VERSION ""

NS_ :

BS_:

BU_: PDCM TCU EMS GCU MCUF MCUR SWM ExternalTool

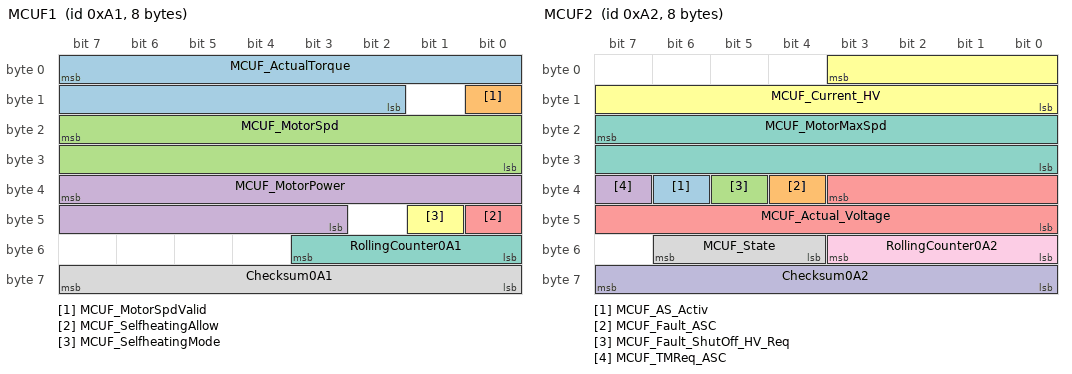
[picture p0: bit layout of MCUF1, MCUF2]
BO_ 161 MCUF1: 8 MCUF
 SG_ MCUF_ActualTorque : 7|14@0+ (0.1,-450) [-450|450] "Nm"  PDCM,TCU
 SG_ MCUF_MotorSpdValid : 8|1@0+ (1,0) [0|1] ""  PDCM,TCU
 SG_ MCUF_MotorSpd : 23|16@0+ (1,-20000) [-20000|20000] "rpm"  PDCM,TCU
 SG_ MCUF_MotorPower : 39|13@0+ (0.1,-260) [-260|260] "Kw"  PDCM,TCU
 SG_ MCUF_SelfheatingAllow : 40|1@0+ (1,0) [0|1] ""  PDCM
 SG_ MCUF_SelfheatingMode : 41|1@0+ (1,0) [0|1] ""  PDCM
 SG_ RollingCounter0A1 : 51|4@0+ (1,0) [0|15] ""  PDCM,TCU
 SG_ Checksum0A1 : 63|8@0+ (1,0) [0|255] ""  PDCM,TCU

BO_ 162 MCUF2: 8 MCUF
 SG_ MCUF_AS_Activ : 38|1@0+ (1,0) [0|1] ""  PDCM
 SG_ MCUF_Fault_ASC : 36|1@0+ (1,0) [0|1] ""  PDCM
 SG_ MCUF_Fault_ShutOff_HV_Req : 37|1@0+ (1,0) [0|1] ""  PDCM
 SG_ MCUF_TMReq_ASC : 39|1@0+ (1,0) [0|1] ""  PDCM
 SG_ MCUF_Actual_Voltage : 35|12@0+ (0.25,0) [0|1023.25] "V"  PDCM
 SG_ MCUF_Current_HV : 3|12@0+ (0.5,-1023) [-1023|1023.5] "Unit_Amper"  PDCM
 SG_ MCUF_MotorMaxSpd : 23|16@0+ (1,-20000) [-20000|20000] "rpm"  PDCM
 SG_ MCUF_State : 54|3@0+ (1,0) [0|7] ""  PDCM
 SG_ RollingCounter0A2 : 51|4@0+ (1,0) [0|15] ""  PDCM
 SG_ Checksum0A2 : 63|8@0+ (1,0) [0|255] ""  PDCM

BO_ 164 MCUF_SelfHeat2: 8 MCUF
 SG_ MCUF_BusCurrent : 18|11@0+ (0.5,0) [0|800] "Arms"  PDCM
 SG_ MCUF_BusFreq : 35|12@0+ (1,0) [0|4000] "Hz"  PDCM

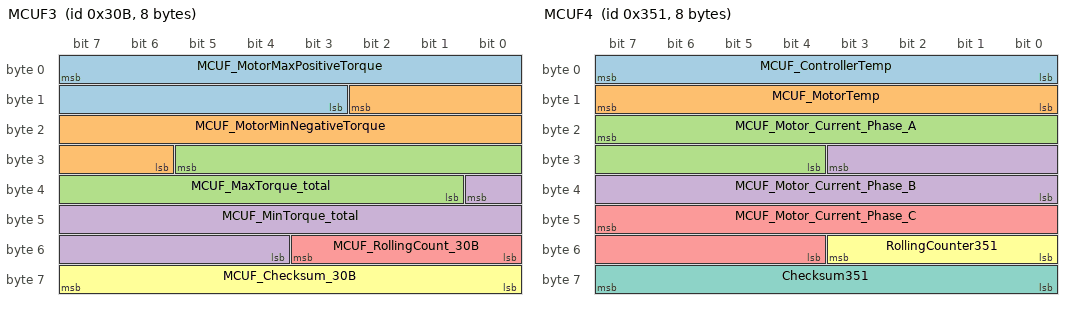
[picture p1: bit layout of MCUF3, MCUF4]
BO_ 779 MCUF3: 8 MCUF
 SG_ MCUF_MotorMaxPositiveTorque : 7|13@0+ (0.1,0) [0|450] ""  PDCM
 SG_ MCUF_MotorMinNegativeTorque : 10|13@0+ (0.1,-450) [-450|0] ""  PDCM
 SG_ MCUF_MaxTorque_total : 29|13@0+ (0.1,0) [0|450] "Unit_NewtoMeter"  PDCM
 SG_ MCUF_MinTorque_total : 32|13@0+ (0.1,-450) [-450|0] "Unit_NewtoMeter"  PDCM
 SG_ MCUF_RollingCount_30B : 51|4@0+ (1,0) [0|15] ""  PDCM
 SG_ MCUF_Checksum_30B : 63|8@0+ (1,0) [0|255] ""  PDCM

BO_ 849 MCUF4: 8 MCUF
 SG_ MCUF_ControllerTemp : 7|8@0+ (1,-40) [-40|214] "℃"  PDCM
 SG_ MCUF_MotorTemp : 15|8@0+ (1,-40) [-40|214] "℃"  PDCM,TCU
 SG_ MCUF_Motor_Current_Phase_A : 23|12@0+ (1,-1200) [-1200|1200] "Unit_Amper"  Vector__XXX
 SG_ MCUF_Motor_Current_Phase_B : 27|12@0+ (1,-1200) [-1200|1200] "Unit_Amper"  Vector__XXX
 SG_ MCUF_Motor_Current_Phase_C : 47|12@0+ (1,-1200) [-1200|1200] "Unit_Amper"  Vector__XXX
 SG_ RollingCounter351 : 51|4@0+ (1,0) [0|15] ""  PDCM,TCU
 SG_ Checksum351 : 63|8@0+ (1,0) [0|255] ""  PDCM,TCU

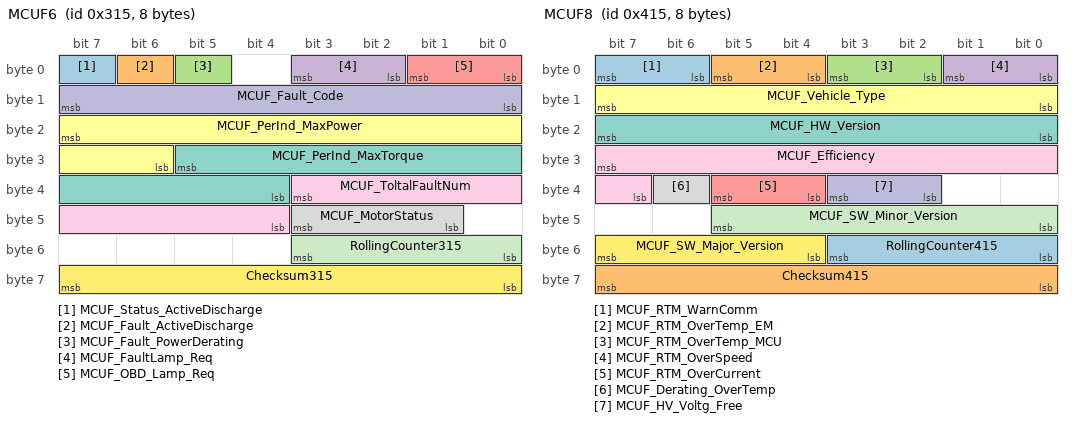
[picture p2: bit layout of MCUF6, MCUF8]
BO_ 789 MCUF6: 8 MCUF
 SG_ MCUF_Status_ActiveDischarge : 7|1@0+ (1,0) [0|1] ""  PDCM
 SG_ MCUF_Fault_ActiveDischarge : 6|1@0+ (1,0) [0|1] ""  PDCM
 SG_ MCUF_Fault_PowerDerating : 5|1@0+ (1,0) [0|1] ""  PDCM
 SG_ MCUF_FaultLamp_Req : 3|2@0+ (1,0) [0|3] ""  PDCM
 SG_ MCUF_OBD_Lamp_Req : 1|2@0+ (1,0) [0|3] ""  PDCM
 SG_ MCUF_PerInd_MaxPower : 23|10@0+ (0.2,0) [0|200] "Unit_Percent"  PDCM
 SG_ MCUF_PerInd_MaxTorque : 29|10@0+ (0.2,0) [0|200] "Unit_Percent"  PDCM
 SG_ MCUF_MotorStatus : 43|3@0+ (1,0) [0|7] ""  PDCM
 SG_ MCUF_ToltalFaultNum : 35|8@0+ (1,0) [0|252] ""  PDCM
 SG_ MCUF_Fault_Code : 15|8@0+ (1,0) [0|255] ""  PDCM
 SG_ RollingCounter315 : 51|4@0+ (1,0) [0|15] ""  PDCM
 SG_ Checksum315 : 63|8@0+ (1,0) [0|255] ""  PDCM

BO_ 787 MCUF_SelfHeat1: 8 MCUF
 SG_ MCUF_UdFreq : 2|11@0+ (1,0) [0|2000] "Hz"  PDCM
 SG_ MCUF_UdVolt : 21|14@0+ (0.1,-500) [-500|500] "V"  PDCM

BO_ 1045 MCUF8: 8 MCUF
 SG_ MCUF_RTM_WarnComm : 7|2@0+ (1,0) [0|3] ""  PDCM
 SG_ MCUF_RTM_OverTemp_EM : 5|2@0+ (1,0) [0|3] ""  PDCM
 SG_ MCUF_RTM_OverTemp_MCU : 3|2@0+ (1,0) [0|3] ""  PDCM
 SG_ MCUF_RTM_OverSpeed : 1|2@0+ (1,0) [0|3] ""  PDCM
 SG_ MCUF_RTM_OverCurrent : 37|2@0+ (1,0) [0|3] ""  PDCM
 SG_ MCUF_Vehicle_Type : 15|8@0+ (1,0) [0|255] ""  PDCM
 SG_ MCUF_HW_Version : 23|8@0+ (1,0) [0|255] ""  PDCM
 SG_ MCUF_Derating_OverTemp : 38|1@0+ (1,0) [0|1] ""  PDCM
 SG_ MCUF_Efficiency : 31|9@0+ (0.2,0) [0|101.8] "Unit_Percent"  PDCM
 SG_ MCUF_HV_Voltg_Free : 35|2@0+ (1,0) [0|3] ""  PDCM
 SG_ MCUF_SW_Minor_Version : 45|6@0+ (1,0) [0|63] ""  PDCM
 SG_ MCUF_SW_Major_Version : 55|4@0+ (1,0) [0|15] ""  PDCM
 SG_ RollingCounter415 : 51|4@0+ (1,0) [0|15] ""  PDCM
 SG_ Checksum415 : 63|8@0+ (1,0) [0|255] ""  PDCM

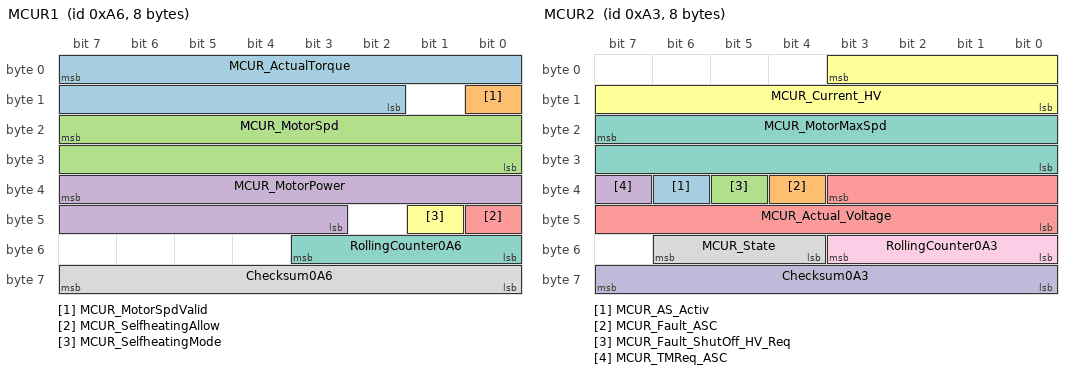
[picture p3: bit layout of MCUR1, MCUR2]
BO_ 166 MCUR1: 8 MCUR
 SG_ MCUR_ActualTorque : 7|14@0+ (0.1,-450) [-450|450] "Nm"  PDCM
 SG_ MCUR_MotorSpdValid : 8|1@0+ (1,0) [0|1] ""  PDCM
 SG_ MCUR_MotorSpd : 23|16@0+ (1,-20000) [-20000|20000] "rpm"  PDCM
 SG_ MCUR_MotorPower : 39|13@0+ (0.1,-260) [-260|260] "Kw"  PDCM
 SG_ MCUR_SelfheatingAllow : 40|1@0+ (1,0) [0|1] ""  PDCM
 SG_ MCUR_SelfheatingMode : 41|1@0+ (1,0) [0|1] ""  PDCM
 SG_ RollingCounter0A6 : 51|4@0+ (1,0) [0|15] ""  PDCM
 SG_ Checksum0A6 : 63|8@0+ (1,0) [0|255] ""  PDCM

BO_ 163 MCUR2: 8 MCUR
 SG_ MCUR_AS_Activ : 38|1@0+ (1,0) [0|1] ""  PDCM
 SG_ MCUR_Fault_ASC : 36|1@0+ (1,0) [0|1] ""  PDCM
 SG_ MCUR_Fault_ShutOff_HV_Req : 37|1@0+ (1,0) [0|1] ""  PDCM
 SG_ MCUR_TMReq_ASC : 39|1@0+ (1,0) [0|1] ""  PDCM
 SG_ MCUR_Actual_Voltage : 35|12@0+ (0.25,0) [0|1023.25] "V"  PDCM
 SG_ MCUR_Current_HV : 3|12@0+ (0.5,-1023) [-1023|1023.5] "Unit_Amper"  PDCM
 SG_ MCUR_MotorMaxSpd : 23|16@0+ (1,-20000) [-20000|20000] "rpm"  PDCM
 SG_ MCUR_State : 54|3@0+ (1,0) [0|7] ""  PDCM
 SG_ RollingCounter0A3 : 51|4@0+ (1,0) [0|15] ""  PDCM
 SG_ Checksum0A3 : 63|8@0+ (1,0) [0|255] ""  PDCM

BO_ 785 MCUR_SelfHeat2: 8 MCUR
 SG_ MCUR_BusCurrent : 18|11@0+ (0.5,0) [0|800] "Arms"  PDCM
 SG_ MCUR_BusFreq : 35|12@0+ (1,0) [0|4000] "Hz"  PDCM

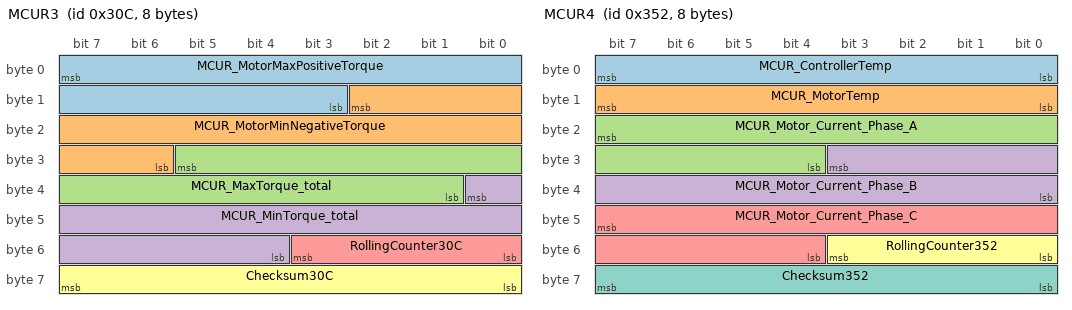
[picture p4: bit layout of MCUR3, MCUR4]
BO_ 780 MCUR3: 8 MCUR
 SG_ MCUR_MotorMaxPositiveTorque : 7|13@0+ (0.1,0) [0|450] ""  PDCM
 SG_ MCUR_MotorMinNegativeTorque : 10|13@0+ (0.1,-450) [-450|0] ""  PDCM
 SG_ MCUR_MaxTorque_total : 29|13@0+ (0.1,0) [0|450] "Unit_NewtoMeter"  PDCM
 SG_ MCUR_MinTorque_total : 32|13@0+ (0.1,-450) [-450|0] "Unit_NewtoMeter"  PDCM
 SG_ RollingCounter30C : 51|4@0+ (1,0) [0|15] ""  PDCM
 SG_ Checksum30C : 63|8@0+ (1,0) [0|255] ""  PDCM

BO_ 850 MCUR4: 8 MCUR
 SG_ MCUR_ControllerTemp : 7|8@0+ (1,-40) [-40|214] "℃"  PDCM
 SG_ MCUR_MotorTemp : 15|8@0+ (1,-40) [-40|214] ""  PDCM
 SG_ MCUR_Motor_Current_Phase_A : 23|12@0+ (1,-1200) [-1200|1200] "Unit_Amper"  Vector__XXX
 SG_ MCUR_Motor_Current_Phase_B : 27|12@0+ (1,-1200) [-1200|1200] "Unit_Amper"  Vector__XXX
 SG_ MCUR_Motor_Current_Phase_C : 47|12@0+ (1,-1200) [-1200|1200] "Unit_Amper"  Vector__XXX
 SG_ RollingCounter352 : 51|4@0+ (1,0) [0|15] ""  PDCM
 SG_ Checksum352 : 63|8@0+ (1,0) [0|255] ""  PDCM

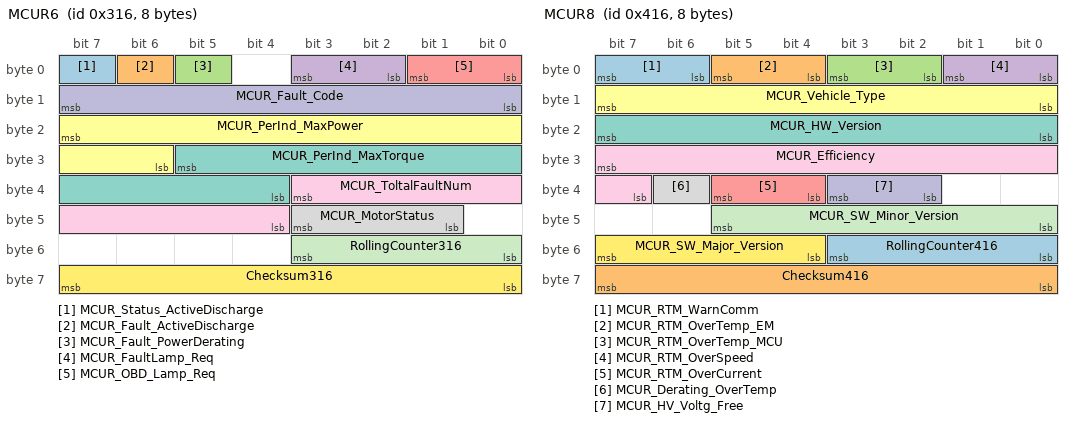
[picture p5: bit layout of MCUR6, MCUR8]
BO_ 790 MCUR6: 8 MCUR
 SG_ MCUR_Status_ActiveDischarge : 7|1@0+ (1,0) [0|1] ""  PDCM
 SG_ MCUR_Fault_ActiveDischarge : 6|1@0+ (1,0) [0|1] ""  PDCM
 SG_ MCUR_Fault_PowerDerating : 5|1@0+ (1,0) [0|1] ""  PDCM
 SG_ MCUR_FaultLamp_Req : 3|2@0+ (1,0) [0|3] ""  PDCM
 SG_ MCUR_OBD_Lamp_Req : 1|2@0+ (1,0) [0|3] ""  PDCM
 SG_ MCUR_PerInd_MaxPower : 23|10@0+ (0.2,0) [0|200] "Unit_Percent"  PDCM
 SG_ MCUR_PerInd_MaxTorque : 29|10@0+ (0.2,0) [0|200] "Unit_Percent"  PDCM
 SG_ MCUR_MotorStatus : 43|3@0+ (1,0) [0|7] ""  PDCM
 SG_ MCUR_ToltalFaultNum : 35|8@0+ (1,0) [0|252] ""  PDCM
 SG_ MCUR_Fault_Code : 15|8@0+ (1,0) [0|255] ""  PDCM
 SG_ RollingCounter316 : 51|4@0+ (1,0) [0|15] ""  PDCM
 SG_ Checksum316 : 63|8@0+ (1,0) [0|255] ""  PDCM

BO_ 786 MCUR_SelfHeat1: 8 MCUR
 SG_ MCUR_UdFreq : 2|11@0+ (1,0) [0|2000] "Hz"  PDCM
 SG_ MCUR_UdVolt : 21|14@0+ (0.1,-500) [-500|500] "V"  PDCM

BO_ 1046 MCUR8: 8 MCUR
 SG_ MCUR_RTM_WarnComm : 7|2@0+ (1,0) [0|3] ""  PDCM
 SG_ MCUR_RTM_OverTemp_EM : 5|2@0+ (1,0) [0|3] ""  PDCM
 SG_ MCUR_RTM_OverTemp_MCU : 3|2@0+ (1,0) [0|3] ""  PDCM
 SG_ MCUR_RTM_OverSpeed : 1|2@0+ (1,0) [0|3] ""  PDCM
 SG_ MCUR_RTM_OverCurrent : 37|2@0+ (1,0) [0|3] ""  PDCM
 SG_ MCUR_Vehicle_Type : 15|8@0+ (1,0) [0|255] ""  PDCM
 SG_ MCUR_HW_Version : 23|8@0+ (1,0) [0|255] ""  PDCM
 SG_ MCUR_Derating_OverTemp : 38|1@0+ (1,0) [0|1] ""  PDCM
 SG_ MCUR_Efficiency : 31|9@0+ (0.2,0) [0|101.8] "Unit_Percent"  PDCM
 SG_ MCUR_HV_Voltg_Free : 35|2@0+ (1,0) [0|3] ""  PDCM
 SG_ MCUR_SW_Minor_Version : 45|6@0+ (1,0) [0|63] ""  PDCM
 SG_ MCUR_SW_Major_Version : 55|4@0+ (1,0) [0|15] ""  PDCM
 SG_ RollingCounter416 : 51|4@0+ (1,0) [0|15] ""  PDCM
 SG_ Checksum416 : 63|8@0+ (1,0) [0|255] ""  PDCM

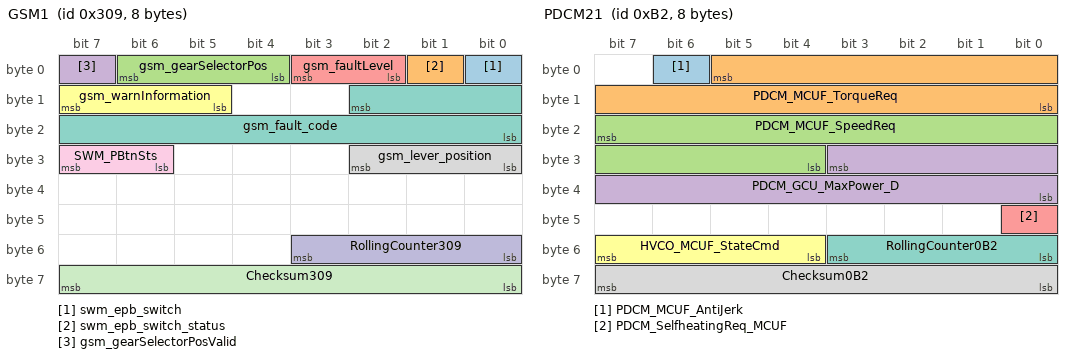
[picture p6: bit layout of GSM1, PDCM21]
BO_ 777 GSM1: 8 SWM
 SG_ swm_epb_switch : 0|1@0+ (1,0) [0|1] ""  PDCM
 SG_ swm_epb_switch_status : 1|1@0+ (1,0) [0|1] ""  PDCM
 SG_ gsm_gearSelectorPos : 6|3@0+ (1,0) [0|7] ""  PDCM
 SG_ gsm_gearSelectorPosValid : 7|1@0+ (1,0) [0|1] ""  PDCM
 SG_ gsm_faultLevel : 3|2@0+ (1,0) [0|3] ""  PDCM
 SG_ gsm_warnInformation : 15|3@0+ (1,0) [0|7] ""  PDCM
 SG_ gsm_fault_code : 10|11@0+ (1,0) [0|2047] ""  PDCM
 SG_ gsm_lever_position : 26|3@0+ (1,0) [0|7] ""  PDCM
 SG_ SWM_PBtnSts : 31|2@0+ (1,0) [0|3] ""  PDCM
 SG_ RollingCounter309 : 51|4@0+ (1,0) [0|15] ""  PDCM
 SG_ Checksum309 : 63|8@0+ (1,0) [0|255] ""  PDCM

BO_ 660 GSM_OBD_alertMatrix0: 8 SWM
 SG_ GSM_OBD_F000_BusOFF_Sts : 1|2@0+ (1,0) [0|3] ""  PDCM
 SG_ GSM_OBD_F001_BatVolHigh_Sts : 3|2@0+ (1,0) [0|3] ""  PDCM
 SG_ GSM_OBD_F002_BatVolLow_Sts : 5|2@0+ (1,0) [0|3] ""  PDCM
 SG_ GSM_OBD_F003_KnobClamp_Sts : 7|2@0+ (1,0) [0|3] ""  PDCM
 SG_ GSM_OBD_F004_SensorFlt_Sts : 9|2@0+ (1,0) [0|3] ""  PDCM
 SG_ GSM_OBD_F005_HALLAgMagicOut_Sts : 11|2@0+ (1,0) [0|3] ""  PDCM
 SG_ GSM_OBD_F006_HALLChipSpiComFlt_Sts : 13|2@0+ (1,0) [0|3] ""  PDCM
 SG_ GSM_OBD_F007_DblPBtnDif_Sts : 15|2@0+ (1,0) [0|3] ""  PDCM
 SG_ GSM_OBD_F008_ParkBtnAdheFlt_Sts : 17|2@0+ (1,0) [0|3] ""  PDCM
 SG_ GSM_OBD_F009_ParkBtnCircFlt_Sts : 19|2@0+ (1,0) [0|3] ""  PDCM
 SG_ GSM_OBD_F00A_UnlckBtnAdheFlt_Sts : 21|2@0+ (1,0) [0|3] ""  PDCM
 SG_ GSM_OBD_F00B_UnlckBtnCircFlt_Sts : 23|2@0+ (1,0) [0|3] ""  PDCM
 SG_ GSM_OBD_F00C_GlbTimeoutPT_Sts : 25|2@0+ (1,0) [0|3] ""  PDCM
 SG_ GSM_OBD_F00D_BackLiDriverFlt_Sts : 27|2@0+ (1,0) [0|3] ""  PDCM
 SG_ GSM_OBD_F00E_GearIndiDriverFlt_Sts : 29|2@0+ (1,0) [0|3] ""  PDCM
 SG_ GSM_OBD_F00F_RAM_Flt_Sts : 31|2@0+ (1,0) [0|3] ""  PDCM
 SG_ GSM_OBD_F010_ROMFlt_Sts : 33|2@0+ (1,0) [0|3] ""  PDCM
 SG_ GSM_OBD_F011_EEPROMFlt_Sts : 35|2@0+ (1,0) [0|3] ""  PDCM
 SG_ GSM_OBD_F012_WdgFlt_Sts : 37|2@0+ (1,0) [0|3] ""  PDCM
 SG_ GSM_OBD_F013_LostComWithPDCM_Sts : 39|2@0+ (1,0) [0|3] ""  PDCM
 SG_ GSM_OBD_F014_SigInvldPDCM10_Sts : 41|2@0+ (1,0) [0|3] ""  PDCM
 SG_ GSM_OBD_F015_SigInvldWithIC_Sts : 43|2@0+ (1,0) [0|3] ""  PDCM
 SG_ GSM_OBD_F016_LostComWithIVI_Sts : 45|2@0+ (1,0) [0|3] ""  PDCM
 SG_ GSM_OBD_F017_SigInvldWithIVI_Sts : 47|2@0+ (1,0) [0|3] ""  PDCM
 SG_ GSM_OBD_F018_LostComWithBCM_Sts : 49|2@0+ (1,0) [0|3] ""  PDCM
 SG_ GSM_OBD_F019_SigInvldWithBCM_Sts : 51|2@0+ (1,0) [0|3] ""  PDCM
 SG_ GSM_OBD_F01A_LostComWithIPB_Sts : 53|2@0+ (1,0) [0|3] ""  PDCM
 SG_ GSM_OBD_F01B_SigInvldWithIPB7_Sts : 55|2@0+ (1,0) [0|3] ""  PDCM
 SG_ GSM_OBD_FaultClrsts : 56|1@0+ (1,0) [0|1] ""  PDCM
 SG_ GSM_OBD_F01C_LostComWithIC_Sts : 58|2@0+ (1,0) [0|3] ""  PDCM

BO_ 712 PDCM10: 8 PDCM
 SG_ PDCM_actualGearValid : 7|1@0+ (1,0) [0|1] ""  TCU,EMS,GCU,MCUF,MCUR,SWM
 SG_ PDCM_targetGearValid : 6|1@0+ (1,0) [0|1] ""  GCU,MCUF
 SG_ PDCM_actualGear : 5|2@0+ (1,0) [0|3] ""  TCU,EMS,GCU,MCUF,MCUR,SWM
 SG_ PDCM_targetGear : 3|2@0+ (1,0) [0|3] ""  GCU,MCUF
 SG_ PDCM_AccelPedal_Status : 1|10@0+ (0.1,0) [0|100] "%"  TCU,EMS,GCU,MCUF,MCUR
 SG_ PDCM_BrakePedal_Valid : 32|1@0+ (1,0) [0|1] ""  TCU,EMS,GCU,MCUF
 SG_ PDCM_BrakePedal_Status : 37|1@0+ (1,0) [0|1] ""  TCU,EMS,GCU,MCUF
 SG_ PDCM_BrakePedal_PressRemind : 38|1@0+ (1,0) [0|1] ""  GCU,MCUF
 SG_ PDCM_AccelPedal_Valid : 39|1@0+ (1,0) [0|1] ""  TCU,EMS,GCU,MCUF,MCUR
 SG_ PDCM_APADrvAst_allow : 30|1@0+ (1,0) [0|1] ""  GCU,MCUF
 SG_ PDCM_ACCDrvAst_allow : 29|1@0+ (1,0) [0|1] ""  GCU,MCUF
 SG_ PDCM_Gear_intervention : 28|1@0+ (1,0) [0|1] ""  GCU,MCUF
 SG_ PDCM_DriveReady : 27|2@0+ (1,0) [0|3] ""  TCU,EMS,GCU,MCUF,MCUR,SWM
 SG_ PDCM_EVMode_Status : 25|2@0+ (1,0) [0|3] ""  EMS,GCU,MCUF
 SG_ PDCM_VehicleSpeed : 23|9@0+ (1,-100) [-100|300] ""  EMS,GCU,MCUF,MCUR,SWM
 SG_ PDCM_driveMode : 42|3@0+ (1,0) [0|7] ""  GCU,MCUF
 SG_ PDCM_driveMode_HW : 45|3@0+ (1,0) [0|7] ""  Vector__XXX
 SG_ PDCM_authenticationResult : 36|2@0+ (1,0) [0|3] ""  GCU,MCUF
 SG_ HV_Network_active : 34|1@0+ (1,0) [0|1] ""  TCU,EMS,GCU,MCUF,MCUR,SWM
 SG_ HV_Network_Fault : 33|1@0+ (1,0) [0|1] ""  TCU,EMS,GCU,MCUF,MCUR,SWM
 SG_ RollingCounter2C8 : 51|4@0+ (1,0) [0|15] ""  TCU,EMS,GCU,MCUF,MCUR,SWM
 SG_ Checksum2C8 : 63|8@0+ (1,0) [0|255] ""  TCU,EMS,GCU,MCUF,MCUR,SWM

BO_ 178 PDCM21: 8 PDCM
 SG_ PDCM_MCUF_AntiJerk : 6|1@0+ (1,0) [0|1] ""  GCU,MCUF,MCUR
 SG_ PDCM_MCUF_TorqueReq : 5|14@0+ (0.1,-512) [-512|512] "Nm"  GCU,MCUF,MCUR
 SG_ PDCM_MCUF_SpeedReq : 23|12@0+ (1,-2000) [-2000|2000] "rpm"  GCU,MCUF,MCUR
 SG_ PDCM_GCU_MaxPower_D : 27|12@0+ (0.1,-150) [-150|150] "Kw"  GCU,MCUF
 SG_ PDCM_SelfheatingReq_MCUF : 40|1@0+ (1,0) [0|1] ""  GCU,MCUF
 SG_ HVCO_MCUF_StateCmd : 55|4@0+ (1,0) [0|14] ""  GCU,MCUF,MCUR
 SG_ RollingCounter0B2 : 51|4@0+ (1,0) [0|15] ""  GCU,MCUF,MCUR
 SG_ Checksum0B2 : 63|8@0+ (1,0) [0|255] ""  GCU,MCUF,MCUR

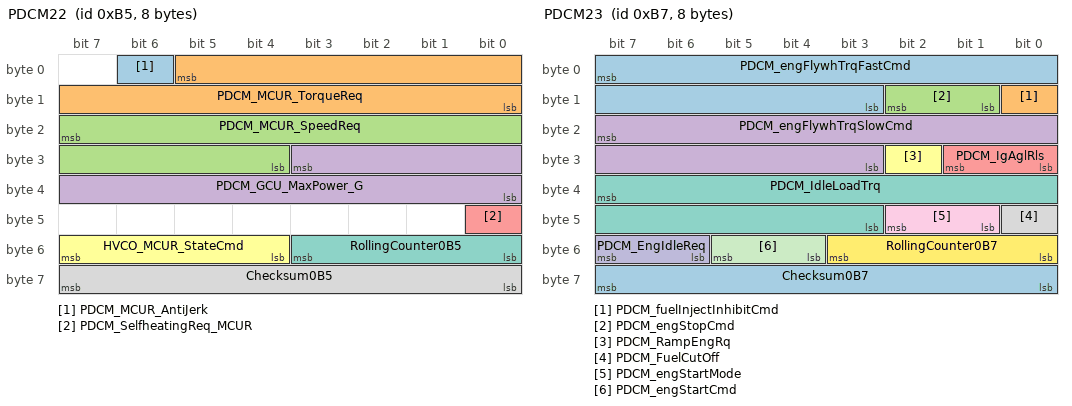
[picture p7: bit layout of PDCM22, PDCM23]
BO_ 181 PDCM22: 8 PDCM
 SG_ PDCM_MCUR_AntiJerk : 6|1@0+ (1,0) [0|1] ""  GCU,MCUF,MCUR
 SG_ PDCM_MCUR_TorqueReq : 5|14@0+ (0.1,-512) [-512|512] "Nm"  GCU,MCUF,MCUR
 SG_ PDCM_MCUR_SpeedReq : 23|12@0+ (1,-2000) [-2000|2000] "rpm"  GCU,MCUF,MCUR
 SG_ PDCM_GCU_MaxPower_G : 27|12@0+ (0.1,-150) [-150|150] "Kw"  GCU,MCUF
 SG_ PDCM_SelfheatingReq_MCUR : 40|1@0+ (1,0) [0|1] ""  GCU,MCUF,MCUR
 SG_ HVCO_MCUR_StateCmd : 55|4@0+ (1,0) [0|14] ""  GCU,MCUF,MCUR
 SG_ RollingCounter0B5 : 51|4@0+ (1,0) [0|15] ""  GCU,MCUF,MCUR
 SG_ Checksum0B5 : 63|8@0+ (1,0) [0|255] ""  GCU,MCUF,MCUR

BO_ 183 PDCM23: 8 PDCM
 SG_ PDCM_engFlywhTrqFastCmd : 7|13@0+ (0.1,-350) [-350|400] "Nm"  EMS
 SG_ PDCM_fuelInjectInhibitCmd : 8|1@0+ (1,0) [0|1] ""  EMS
 SG_ PDCM_engStopCmd : 10|2@0+ (1,0) [0|3] ""  EMS
 SG_ PDCM_engFlywhTrqSlowCmd : 23|13@0+ (0.1,-350) [-350|400] "Nm"  EMS
 SG_ PDCM_IgAglRls : 25|2@0+ (1,0) [0|3] ""  EMS
 SG_ PDCM_RampEngRq : 26|1@0+ (1,0) [0|1] ""  EMS
 SG_ PDCM_IdleLoadTrq : 39|13@0+ (0.1,-350) [-350|400] ""  EMS
 SG_ PDCM_FuelCutOff : 40|1@0+ (1,0) [0|1] ""  EMS
 SG_ PDCM_engStartMode : 42|2@0+ (1,0) [0|3] ""  EMS
 SG_ PDCM_EngIdleReq : 55|2@0+ (1,0) [0|3] ""  EMS
 SG_ PDCM_engStartCmd : 53|2@0+ (1,0) [0|3] ""  EMS
 SG_ RollingCounter0B7 : 51|4@0+ (1,0) [0|15] ""  EMS
 SG_ Checksum0B7 : 63|8@0+ (1,0) [0|255] ""  EMS

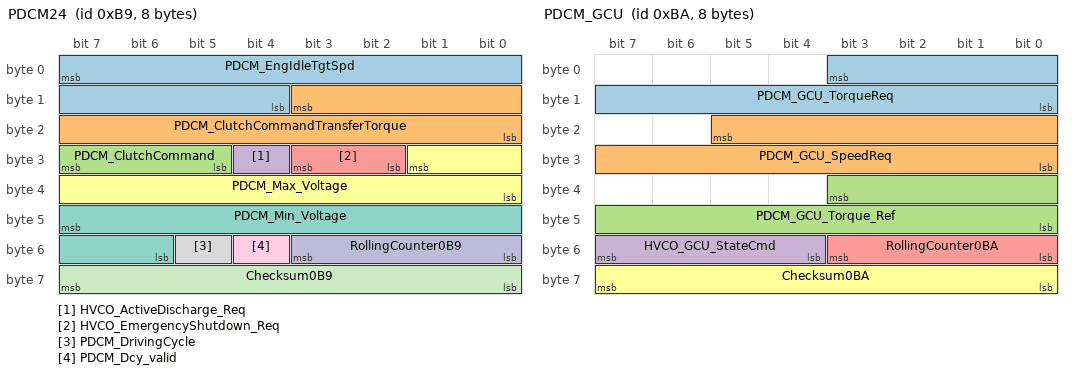
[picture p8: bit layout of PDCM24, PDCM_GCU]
BO_ 185 PDCM24: 8 PDCM
 SG_ PDCM_EngIdleTgtSpd : 7|12@0+ (1,0) [0|4095] ""  EMS,GCU,MCUF
 SG_ PDCM_ClutchCommandTransferTorque : 11|12@0+ (0.125,-100) [-100|411.75] "Nm"  TCU,GCU,MCUF
 SG_ PDCM_ClutchCommand : 31|3@0+ (1,0) [0|7] ""  TCU,GCU,MCUF
 SG_ HVCO_ActiveDischarge_Req : 28|1@0+ (1,0) [0|1] ""  GCU,MCUF,MCUR
 SG_ HVCO_EmergencyShutdown_Req : 27|2@0+ (1,0) [0|3] ""  EMS,GCU,MCUF,MCUR
 SG_ PDCM_Max_Voltage : 25|10@0+ (1,0) [0|1022] ""  GCU,MCUF,MCUR
 SG_ PDCM_Min_Voltage : 47|10@0+ (1,0) [0|1022] ""  GCU,MCUF,MCUR
 SG_ PDCM_DrivingCycle : 53|1@0+ (1,0) [0|1] "—"  TCU,EMS,GCU,MCUF,MCUR,SWM
 SG_ PDCM_Dcy_valid : 52|1@0+ (1,0) [0|1] ""  TCU,EMS,GCU,MCUF,MCUR,SWM
 SG_ RollingCounter0B9 : 51|4@0+ (1,0) [0|15] ""  TCU,EMS,GCU,MCUF,MCUR
 SG_ Checksum0B9 : 63|8@0+ (1,0) [0|255] ""  TCU,EMS,GCU,MCUF,MCUR

BO_ 186 PDCM_GCU: 8 PDCM
 SG_ PDCM_GCU_TorqueReq : 3|12@0+ (0.1,-150) [-150|150] "Nm"  GCU
 SG_ PDCM_GCU_SpeedReq : 21|14@0+ (1,0) [0|15000] "rpm"  GCU
 SG_ PDCM_GCU_Torque_Ref : 35|12@0+ (0.1,-150) [-150|150] ""  GCU
 SG_ HVCO_GCU_StateCmd : 55|4@0+ (1,0) [0|15] ""  GCU
 SG_ RollingCounter0BA : 51|4@0+ (1,0) [0|15] ""  GCU
 SG_ Checksum0BA : 63|8@0+ (1,0) [0|255] ""  GCU

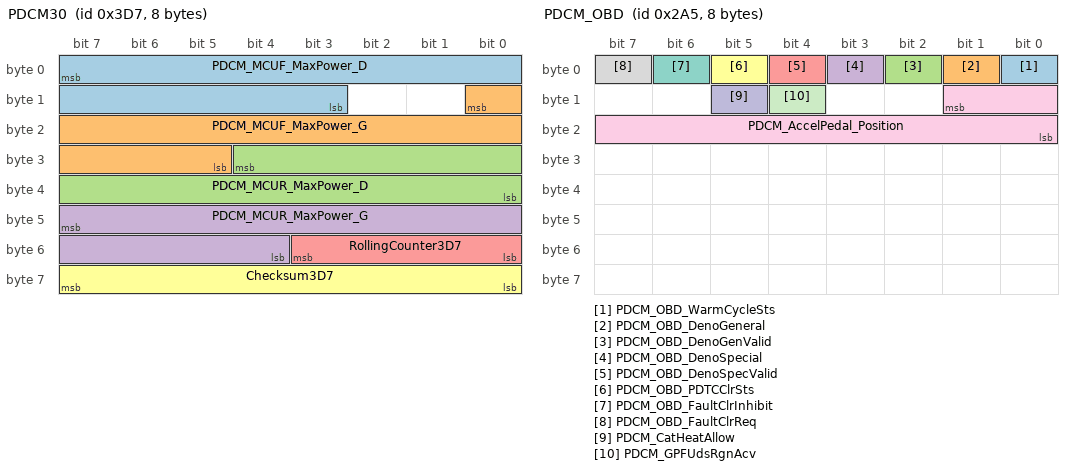
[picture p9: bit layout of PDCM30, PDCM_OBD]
BO_ 983 PDCM30: 8 PDCM
 SG_ PDCM_MCUF_MaxPower_D : 7|13@0+ (0.1,0) [0|500] "KW"  MCUF,MCUR
 SG_ PDCM_MCUF_MaxPower_G : 8|12@0+ (0.1,-300) [-300|0] "KW"  MCUF,MCUR
 SG_ PDCM_MCUR_MaxPower_D : 28|13@0+ (0.1,0) [0|500] "KW"  MCUF,MCUR
 SG_ PDCM_MCUR_MaxPower_G : 47|12@0+ (0.1,-300) [-300|0] "KW"  MCUF,MCUR
 SG_ RollingCounter3D7 : 51|4@0+ (1,0) [0|15] ""  MCUF,MCUR
 SG_ Checksum3D7 : 63|8@0+ (1,0) [0|255] ""  MCUF,MCUR

BO_ 854 PDCM_SelfHeat: 8 PDCM
 SG_ PDCM_SelfheatingMode : 0|1@0+ (1,0) [0|1] ""  MCUF,MCUR
 SG_ PDCM_MainCoolPumpReqDC : 14|7@0+ (1,0) [0|100] "%"  EMS

BO_ 645 PDCM1: 8 PDCM
 SG_ HVEM_HV_Req : 43|1@0+ (1,0) [0|1] ""  GCU,MCUF
 SG_ HVEM_Power_Aux : 23|9@0+ (0.05,0) [0|25.45] "Unit_Watt"  GCU,MCUF
 SG_ HVEM_Current_HVAux : 39|12@0+ (0.1,-204.7) [-204.7|204.6] "Unit_Amper"  GCU,MCUF
 SG_ PDCM_SOC : 42|11@0+ (0.05,0) [0|100] "Unit_Percent"  TCU,EMS,GCU,MCUF,MCUR,SWM
 SG_ PDCM_KL15DelayAllow : 60|1@0+ (1,0) [0|1] ""  Vector__XXX

BO_ 677 PDCM_OBD: 8 PDCM
 SG_ PDCM_OBD_WarmCycleSts : 0|1@0+ (1,0) [0|1] ""  TCU,EMS,GCU,MCUF,MCUR
 SG_ PDCM_OBD_DenoGeneral : 1|1@0+ (1,0) [0|1] ""  TCU,EMS,GCU,MCUF,MCUR
 SG_ PDCM_OBD_DenoGenValid : 2|1@0+ (1,0) [0|1] ""  TCU,EMS,GCU,MCUF,MCUR
 SG_ PDCM_OBD_DenoSpecial : 3|1@0+ (1,0) [0|1] ""  TCU,EMS,GCU,MCUF,MCUR
 SG_ PDCM_OBD_DenoSpecValid : 4|1@0+ (1,0) [0|1] ""  TCU,EMS,GCU,MCUF,MCUR
 SG_ PDCM_OBD_PDTCClrSts : 5|1@0+ (1,0) [0|1] ""  TCU,EMS,GCU,MCUF,MCUR
 SG_ PDCM_OBD_FaultClrInhibit : 6|1@0+ (1,0) [0|1] ""  TCU,EMS,GCU,MCUF,MCUR
 SG_ PDCM_OBD_FaultClrReq : 7|1@0+ (1,0) [0|1] ""  GCU,MCUF,SWM
 SG_ PDCM_AccelPedal_Position : 9|10@0+ (0.1,0) [0|100] "%"  TCU,EMS,GCU,MCUF,MCUR
 SG_ PDCM_CatHeatAllow : 13|1@0+ (1,0) [0|1] ""  EMS,GCU,MCUF
 SG_ PDCM_GPFUdsRgnAcv : 12|1@0+ (1,0) [0|1] ""  EMS,GCU,MCUF

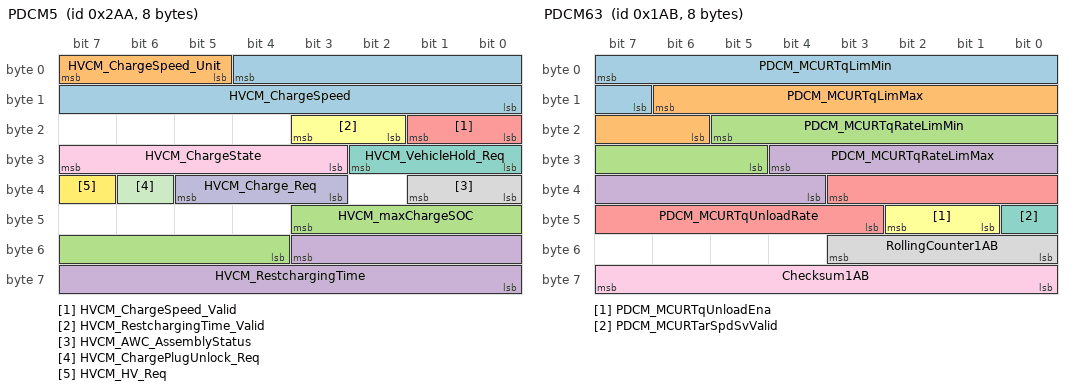
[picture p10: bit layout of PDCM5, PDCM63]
BO_ 682 PDCM5: 8 PDCM
 SG_ HVCM_ChargeSpeed : 4|13@0+ (1,0) [0|5000] "Unit_None"  GCU,MCUF
 SG_ HVCM_ChargeSpeed_Unit : 7|3@0+ (1,0) [0|7] ""  GCU,MCUF
 SG_ HVCM_maxChargeSOC : 43|8@0+ (1,0) [0|100] "%"  GCU,MCUF
 SG_ HVCM_RestchargingTime : 51|12@0+ (1,0) [0|2880] "Unit_Minut"  GCU,MCUF
 SG_ HVCM_ChargeSpeed_Valid : 17|2@0+ (1,0) [0|3] ""  GCU,MCUF
 SG_ HVCM_RestchargingTime_Valid : 19|2@0+ (1,0) [0|3] ""  GCU,MCUF
 SG_ HVCM_VehicleHold_Req : 26|3@0+ (1,0) [0|7] ""  GCU,MCUF
 SG_ HVCM_AWC_AssemblyStatus : 33|2@0+ (1,0) [0|3] ""  GCU,MCUF
 SG_ HVCM_ChargeState : 31|5@0+ (1,0) [0|31] ""  TCU,EMS,GCU,MCUF,MCUR,SWM
 SG_ HVCM_Charge_Req : 37|3@0+ (1,0) [0|7] ""  GCU,MCUF
 SG_ HVCM_ChargePlugUnlock_Req : 38|1@0+ (1,0) [0|1] ""  GCU,MCUF
 SG_ HVCM_HV_Req : 39|1@0+ (1,0) [0|1] ""  GCU,MCUF

BO_ 1135 PDCM38: 8 PDCM
 SG_ TM_Temp_senser_1 : 7|9@0+ (0.5,-40) [-40|125] ""  MCUF,MCUR
 SG_ TM_Temp_senser_2 : 14|9@0+ (0.5,-40) [-40|125] ""  MCUF,MCUR
 SG_ RollingCounter46F : 51|4@0+ (1,0) [0|15] ""  MCUF,MCUR
 SG_ Checksum46F : 63|8@0+ (1,0) [0|255] ""  MCUF,MCUR

BO_ 427 PDCM63: 8 PDCM
 SG_ PDCM_MCURTqLimMin : 7|9@0+ (2,-450) [-450|450] "Nm"  MCUR
 SG_ PDCM_MCURTqLimMax : 14|9@0+ (2,-450) [-450|450] "Nm"  MCUR
 SG_ PDCM_MCURTqRateLimMin : 21|9@0+ (5,-1275) [-1275|1275] "Nm/s"  MCUR
 SG_ PDCM_MCURTqRateLimMax : 28|9@0+ (5,-1275) [-1275|1275] "Nm/s"  MCUR
 SG_ PDCM_MCURTqUnloadRate : 35|9@0+ (5,-1275) [-1275|1275] "Nm/s"  MCUR
 SG_ PDCM_MCURTqUnloadEna : 42|2@0+ (1,0) [0|3] ""  MCUR
 SG_ PDCM_MCURTarSpdSvValid : 40|1@0+ (1,0) [0|1] ""  MCUR
 SG_ RollingCounter1AB : 51|4@0+ (1,0) [0|15] ""  MCUR
 SG_ Checksum1AB : 63|8@0+ (1,0) [0|255] ""  MCUR

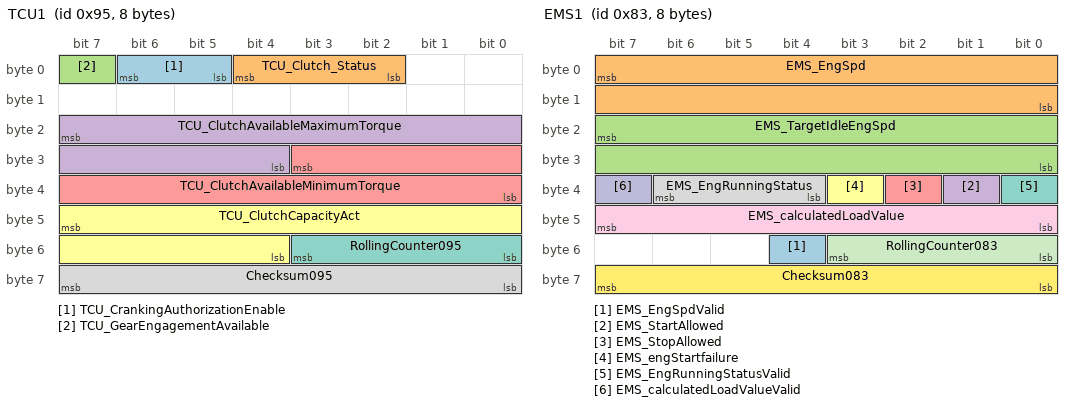
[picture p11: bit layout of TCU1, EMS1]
BO_ 149 TCU1: 8 TCU
 SG_ TCU_CrankingAuthorizationEnable : 6|2@0+ (1,0) [0|2] "—"  PDCM
 SG_ TCU_Clutch_Status : 4|3@0+ (1,0) [0|7] "_"  PDCM,EMS
 SG_ TCU_GearEngagementAvailable : 7|1@0+ (1,0) [0|1] "—"  PDCM
 SG_ TCU_ClutchAvailableMaximumTorque : 23|12@0+ (0.125,-100) [-100|411.75] "Nm"  PDCM
 SG_ TCU_ClutchAvailableMinimumTorque : 27|12@0+ (0.125,-100) [-100|411.75] "Nm"  PDCM
 SG_ TCU_ClutchCapacityAct : 47|12@0+ (0.125,-100) [-100|411.75] "Nm"  PDCM
 SG_ RollingCounter095 : 51|4@0+ (1,0) [0|15] "—"  PDCM,EMS
 SG_ Checksum095 : 63|8@0+ (1,0) [0|255] "—"  PDCM,EMS

BO_ 151 TCU2: 8 TCU
 SG_ TCU_MaxFrtMotPwr_Req : 7|13@0+ (0.1,-260) [-260|260] ""  PDCM
 SG_ TCU_Fault_Reaction_Req : 31|4@0+ (1,0) [0|15] ""  PDCM
 SG_ TCU_MaxGCUPwr_Req : 27|12@0+ (0.1,-150) [-150|150] ""  PDCM
 SG_ RollingCounter097 : 51|4@0+ (1,0) [0|15] "—"  PDCM
 SG_ Checksum097 : 63|8@0+ (1,0) [0|255] "—"  PDCM

BO_ 817 TCU3: 8 TCU
 SG_ TCU_OBD_Lamp_Req : 1|2@0+ (1,0) [0|3] "—"  PDCM
 SG_ TCU_FaultLamp_Req : 6|2@0+ (1,0) [0|3] ""  PDCM
 SG_ TCU_TransmissionFluidTemp : 47|8@0+ (1,-40) [-40|214] "℃"  PDCM
 SG_ TCU_AirFlowRequest : 39|8@0+ (0.5,0) [0|100] "%"  PDCM
 SG_ RollingCounter331 : 51|4@0+ (1,0) [0|15] "—"  PDCM
 SG_ Checksum331 : 63|8@0+ (1,0) [0|255] "—"  PDCM

BO_ 131 EMS1: 8 EMS
 SG_ EMS_EngSpdValid : 52|1@0+ (1,0) [0|1] "—"  PDCM,TCU,GCU,MCUF,MCUR
 SG_ EMS_EngSpd : 7|16@0+ (0.125,0) [0|8191.875] "rpm"  PDCM,TCU,GCU,MCUF,MCUR
 SG_ EMS_TargetIdleEngSpd : 23|16@0+ (0.125,0) [0|8191.875] "rpm"  PDCM,GCU,MCUF
 SG_ EMS_StartAllowed : 33|1@0+ (1,0) [0|1] "—"  PDCM,GCU,MCUF
 SG_ EMS_StopAllowed : 34|1@0+ (1,0) [0|1] "—"  PDCM,GCU,MCUF
 SG_ EMS_engStartfailure : 35|1@0+ (1,0) [0|1] "—"  PDCM,GCU,MCUF
 SG_ EMS_EngRunningStatusValid : 32|1@0+ (1,0) [0|1] "—"  PDCM,TCU,GCU,MCUF
 SG_ EMS_EngRunningStatus : 38|3@0+ (1,0) [0|7] "—"  PDCM,TCU,GCU,MCUF
 SG_ EMS_calculatedLoadValue : 47|8@0+ (0.394,0) [0|100.076] "%"  PDCM,TCU,GCU,MCUF,MCUR
 SG_ EMS_calculatedLoadValueValid : 39|1@0+ (1,0) [0|1] "—"  PDCM,TCU,GCU,MCUF,MCUR
 SG_ RollingCounter083 : 51|4@0+ (1,0) [0|15] "—"  PDCM,TCU,GCU,MCUF
 SG_ Checksum083 : 63|8@0+ (1,0) [0|255] "—"  PDCM,TCU,GCU,MCUF

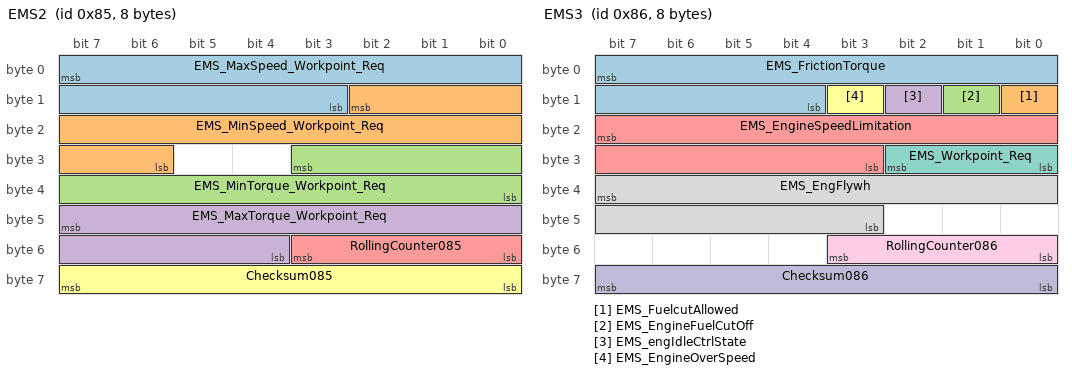
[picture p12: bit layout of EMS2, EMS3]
BO_ 133 EMS2: 8 EMS
 SG_ EMS_MaxSpeed_Workpoint_Req : 7|13@0+ (1,0) [0|8000] "RPM"  PDCM
 SG_ EMS_MinSpeed_Workpoint_Req : 10|13@0+ (1,0) [0|8000] "RPM"  PDCM
 SG_ EMS_MinTorque_Workpoint_Req : 27|12@0+ (0.125,-100) [-100|411.75] "Nm"  PDCM
 SG_ EMS_MaxTorque_Workpoint_Req : 47|12@0+ (0.125,-100) [-100|411.75] "Nm"  PDCM
 SG_ RollingCounter085 : 51|4@0+ (1,0) [0|15] ""  Vector__XXX
 SG_ Checksum085 : 63|8@0+ (1,0) [0|255] ""  Vector__XXX

BO_ 134 EMS3: 8 EMS
 SG_ EMS_FrictionTorque : 7|12@0+ (0.125,-100) [-100|411.75] "Nm"  PDCM,MCUF
 SG_ EMS_FuelcutAllowed : 8|1@0+ (1,0) [0|1] "—"  PDCM,MCUF
 SG_ EMS_EngineFuelCutOff : 9|1@0+ (1,0) [0|1] ""  PDCM,MCUF
 SG_ EMS_engIdleCtrlState : 10|1@0+ (1,0) [0|1] ""  PDCM,MCUF
 SG_ EMS_EngineSpeedLimitation : 23|13@0+ (1,0) [0|8000] "RPM"  PDCM,MCUF
 SG_ EMS_EngineOverSpeed : 11|1@0+ (1,0) [0|1] ""  PDCM,MCUF
 SG_ EMS_Workpoint_Req : 26|3@0+ (1,0) [0|7] ""  PDCM,MCUF
 SG_ EMS_EngFlywh : 39|13@0+ (0.1,-350) [-350|400] "Nm"  PDCM,TCU,MCUF
 SG_ RollingCounter086 : 51|4@0+ (1,0) [0|15] ""  PDCM,TCU,MCUF
 SG_ Checksum086 : 63|8@0+ (1,0) [0|255] ""  PDCM,TCU,MCUF

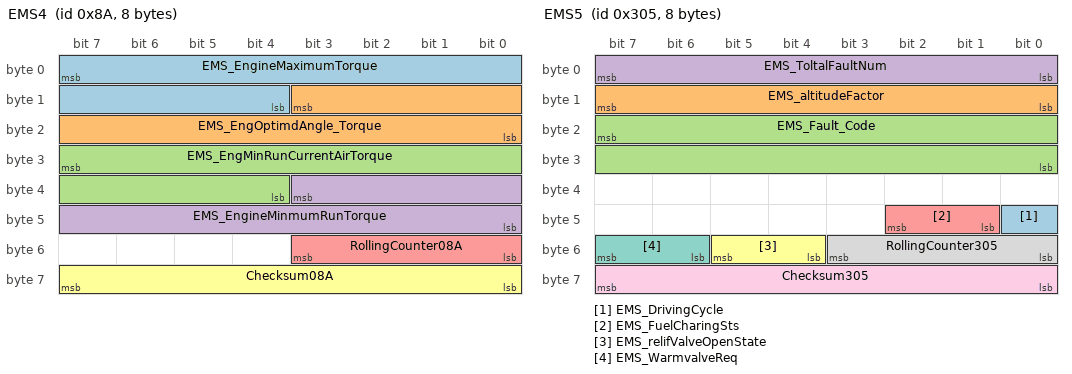
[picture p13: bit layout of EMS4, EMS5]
BO_ 138 EMS4: 8 EMS
 SG_ EMS_EngineMaximumTorque : 7|12@0+ (0.125,-100) [-100|411.875] "Nm"  PDCM
 SG_ EMS_EngOptimdAngle_Torque : 11|12@0+ (0.125,-100) [-100|411.875] "Nm"  PDCM
 SG_ EMS_EngMinRunCurrentAirTorque : 31|12@0+ (0.125,-100) [-100|411.875] "Nm"  PDCM
 SG_ EMS_EngineMinmumRunTorque : 35|12@0+ (0.125,-100) [-100|411.875] "Nm"  PDCM
 SG_ RollingCounter08A : 51|4@0+ (1,0) [0|15] ""  PDCM
 SG_ Checksum08A : 63|8@0+ (1,0) [0|255] ""  PDCM

BO_ 773 EMS5: 8 EMS
 SG_ EMS_DrivingCycle : 40|1@0+ (1,0) [0|1] "—"  PDCM,GCU,MCUF
 SG_ EMS_altitudeFactor : 15|8@0+ (0.01575,0) [0|4.0005] ""  PDCM,TCU,GCU,MCUF,MCUR
 SG_ EMS_Fault_Code : 23|16@0+ (1,0) [0|63225] ""  PDCM,GCU,MCUF
 SG_ EMS_ToltalFaultNum : 7|8@0+ (1,0) [0|252] ""  PDCM,GCU,MCUF
 SG_ EMS_FuelCharingSts : 42|2@0+ (1,0) [0|3] ""  PDCM,GCU,MCUF
 SG_ EMS_relifValveOpenState : 53|2@0+ (1,0) [0|3] ""  PDCM,GCU,MCUF
 SG_ EMS_WarmvalveReq : 55|2@0+ (1,0) [0|3] "—"  PDCM,GCU,MCUF
 SG_ RollingCounter305 : 51|4@0+ (1,0) [0|15] "—"  PDCM,GCU,MCUF
 SG_ Checksum305 : 63|8@0+ (1,0) [0|255] "—"  PDCM,GCU,MCUF

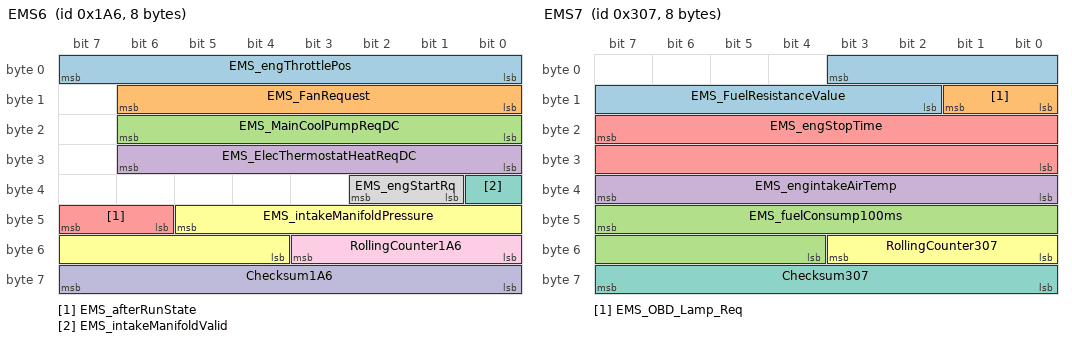
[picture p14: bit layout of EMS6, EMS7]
BO_ 422 EMS6: 8 EMS
 SG_ EMS_engThrottlePos : 7|8@0+ (0.392,0) [0|99.96] "%"  PDCM
 SG_ EMS_FanRequest : 14|7@0+ (1,0) [0|100] "%"  PDCM
 SG_ EMS_MainCoolPumpReqDC : 22|7@0+ (1,0) [0|100] "%"  PDCM
 SG_ EMS_ElecThermostatHeatReqDC : 30|7@0+ (1,0) [0|100] "%"  PDCM
 SG_ EMS_afterRunState : 47|2@0+ (1,0) [0|3] ""  PDCM
 SG_ EMS_intakeManifoldPressure : 45|10@0+ (4,100) [100|4188] "hpa"  PDCM
 SG_ EMS_intakeManifoldValid : 32|1@0+ (1,0) [0|1] ""  PDCM
 SG_ EMS_engStartRq : 34|2@0+ (1,0) [0|3] ""  PDCM
 SG_ RollingCounter1A6 : 51|4@0+ (1,0) [0|15] ""  PDCM
 SG_ Checksum1A6 : 63|8@0+ (1,0) [0|255] ""  PDCM

BO_ 775 EMS7: 8 EMS
 SG_ EMS_FuelResistanceValue : 3|10@0+ (1,0) [0|1023] "Ω"  PDCM
 SG_ EMS_OBD_Lamp_Req : 9|2@0+ (1,0) [0|3] ""  PDCM
 SG_ EMS_fuelConsump100ms : 47|12@0+ (0.001,0) [0|4] "ml"  PDCM
 SG_ EMS_engintakeAirTemp : 39|8@0+ (0.75,-40) [-40|150.5] "C"  PDCM
 SG_ EMS_engStopTime : 23|16@0+ (1,0) [0|65533] "s"  PDCM
 SG_ RollingCounter307 : 51|4@0+ (1,0) [0|15] ""  PDCM
 SG_ Checksum307 : 63|8@0+ (1,0) [0|255] ""  PDCM

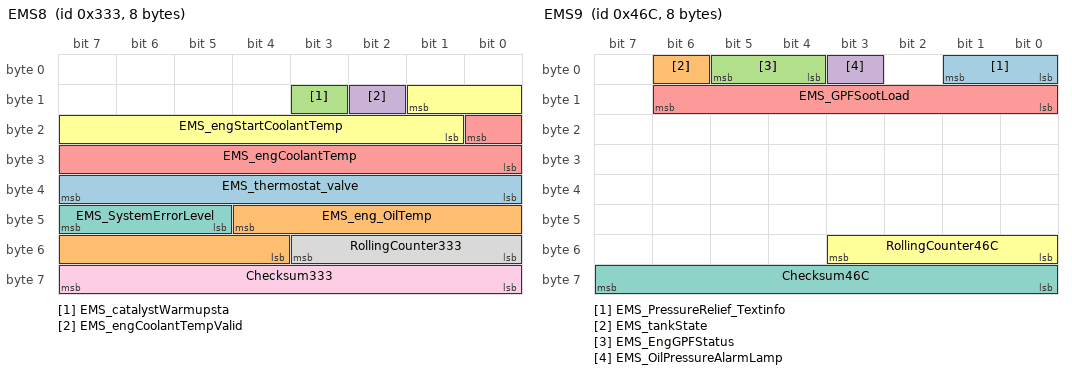
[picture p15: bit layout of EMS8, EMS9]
BO_ 819 EMS8: 8 EMS
 SG_ EMS_thermostat_valve : 39|8@0+ (1,0) [0|100] "%"  PDCM,GCU,MCUF
 SG_ EMS_eng_OilTemp : 44|9@0+ (0.5,-40) [-40|200] "degreeC"  PDCM,TCU,GCU,MCUF,MCUR
 SG_ EMS_catalystWarmupsta : 11|1@0+ (1,0) [0|1] ""  PDCM,TCU,GCU,MCUF
 SG_ EMS_engCoolantTempValid : 10|1@0+ (1,0) [0|1] ""  PDCM,TCU,GCU,MCUF,MCUR
 SG_ EMS_engCoolantTemp : 16|9@0+ (0.5,-40) [-40|140] "degreeC"  PDCM,TCU,GCU,MCUF,MCUR
 SG_ EMS_engStartCoolantTemp : 9|9@0+ (0.5,-40) [-40|140] "degreeC"  PDCM,GCU,MCUF
 SG_ EMS_SystemErrorLevel : 47|3@0+ (1,0) [0|7] "—"  PDCM,GCU,MCUF
 SG_ RollingCounter333 : 51|4@0+ (1,0) [0|15] ""  PDCM,TCU,GCU,MCUF,MCUR
 SG_ Checksum333 : 63|8@0+ (1,0) [0|255] ""  PDCM,TCU,GCU,MCUF,MCUR

BO_ 1132 EMS9: 8 EMS
 SG_ EMS_PressureRelief_Textinfo : 1|2@0+ (1,0) [0|3] "—"  PDCM
 SG_ EMS_tankState : 6|1@0+ (1,0) [0|1] "—"  PDCM
 SG_ EMS_EngGPFStatus : 5|2@0+ (1,0) [0|3] "—"  PDCM
 SG_ EMS_OilPressureAlarmLamp : 3|1@0+ (1,0) [0|1] "—"  PDCM
 SG_ EMS_GPFSootLoad : 14|7@0+ (1,0) [0|100] "%"  PDCM
 SG_ RollingCounter46C : 51|4@0+ (1,0) [0|15] ""  PDCM
 SG_ Checksum46C : 63|8@0+ (1,0) [0|255] ""  PDCM

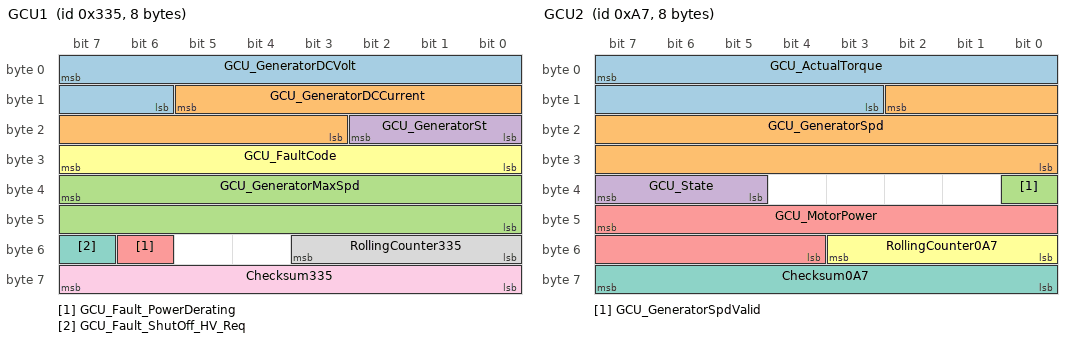
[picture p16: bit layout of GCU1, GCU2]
BO_ 821 GCU1: 8 GCU
 SG_ GCU_GeneratorDCVolt : 7|10@0+ (0.5,0) [0|511] "V"  PDCM
 SG_ GCU_GeneratorDCCurrent : 13|11@0+ (0.5,-500) [-500|500] "A"  PDCM
 SG_ GCU_GeneratorMaxSpd : 39|16@0+ (1,-20000) [-20000|20000] "rpm"  PDCM
 SG_ GCU_GeneratorSt : 18|3@0+ (1,0) [0|7] ""  PDCM
 SG_ GCU_Fault_PowerDerating : 54|1@0+ (1,0) [0|1] ""  PDCM
 SG_ GCU_FaultCode : 31|8@0+ (1,0) [0|255] ""  PDCM
 SG_ GCU_Fault_ShutOff_HV_Req : 55|1@0+ (1,0) [0|1] ""  PDCM
 SG_ RollingCounter335 : 51|4@0+ (1,0) [0|15] ""  PDCM
 SG_ Checksum335 : 63|8@0+ (1,0) [0|255] ""  PDCM

BO_ 167 GCU2: 8 GCU
 SG_ GCU_ActualTorque : 7|13@0+ (0.1,-310) [-310|310] "Nm"  PDCM,TCU,EMS
 SG_ GCU_GeneratorSpd : 10|19@0+ (0.1,-20000) [-20000|20000] "rpm"  PDCM,TCU,EMS
 SG_ GCU_GeneratorSpdValid : 32|1@0+ (1,0) [0|1] ""  PDCM,TCU,EMS
 SG_ GCU_State : 39|3@0+ (1,0) [0|7] ""  PDCM
 SG_ GCU_MotorPower : 47|12@0+ (0.1,-150) [-150|150] "Kw"  PDCM,TCU
 SG_ RollingCounter0A7 : 51|4@0+ (1,0) [0|15] ""  PDCM,TCU,EMS
 SG_ Checksum0A7 : 63|8@0+ (1,0) [0|255] ""  PDCM,TCU,EMS

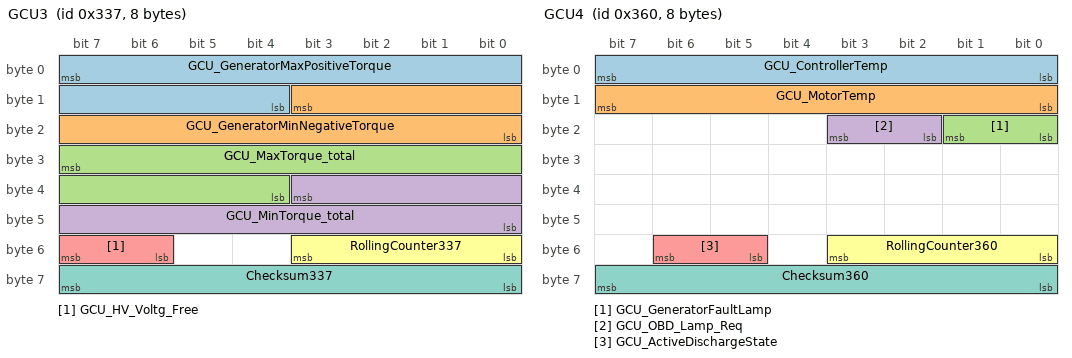
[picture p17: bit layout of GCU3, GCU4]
BO_ 823 GCU3: 8 GCU
 SG_ GCU_GeneratorMaxPositiveTorque : 7|12@0+ (0.1,0) [0|310] ""  PDCM
 SG_ GCU_GeneratorMinNegativeTorque : 11|12@0+ (0.1,-310) [-310|0] ""  PDCM
 SG_ GCU_MaxTorque_total : 31|12@0+ (0.1,0) [0|310] ""  PDCM
 SG_ GCU_MinTorque_total : 35|12@0+ (0.1,-310) [-310|0] ""  PDCM
 SG_ GCU_HV_Voltg_Free : 55|2@0+ (1,0) [0|3] ""  PDCM
 SG_ RollingCounter337 : 51|4@0+ (1,0) [0|15] ""  PDCM
 SG_ Checksum337 : 63|8@0+ (1,0) [0|255] ""  PDCM

BO_ 864 GCU4: 8 GCU
 SG_ GCU_ControllerTemp : 7|8@0+ (1,-40) [-40|215] "℃"  PDCM
 SG_ GCU_MotorTemp : 15|8@0+ (1,-40) [-40|215] "℃"  PDCM,TCU
 SG_ GCU_GeneratorFaultLamp : 17|2@0+ (1,0) [0|3] ""  PDCM
 SG_ GCU_OBD_Lamp_Req : 19|2@0+ (1,0) [0|3] ""  PDCM
 SG_ GCU_ActiveDischargeState : 54|2@0+ (1,0) [0|3] ""  PDCM
 SG_ RollingCounter360 : 51|4@0+ (1,0) [0|15] ""  PDCM,TCU
 SG_ Checksum360 : 63|8@0+ (1,0) [0|255] ""  PDCM,TCU

BO_ 1278 TBOX_VehicleMode: 8 PDCM
 SG_ tbox_vehicleMode : 3|4@0+ (1,0) [0|15] ""  TCU,EMS,GCU,MCUF,MCUR,SWM
 SG_ TBOX_OTAEnergyCtl : 7|4@0+ (1,0) [0|15] ""  GCU,MCUF
 SG_ TBOX_OTATimeSet : 13|6@0+ (5,0) [0|180] "min"  GCU,MCUF
 SG_ RollingCounter4FE : 55|4@0+ (1,0) [0|15] ""  TCU,EMS,GCU,MCUF,MCUR,SWM
 SG_ Checksum4FE : 63|8@0+ (1,0) [0|255] ""  TCU,EMS,GCU,MCUF,MCUR,SWM

BO_ 82 TBOX_engineOFF: 8 PDCM
 SG_ Tbox_engOffTime : 7|10@0+ (1,0) [0|1000] "min"  MCUF,MCUR
 SG_ Tbox_engOffTimeValid : 13|1@0+ (1,0) [0|1] ""  MCUF,MCUR

BO_ 476 IVI_BodySet1: 8 PDCM
 SG_ ivi_centralLockCtrl : 1|2@0+ (1,0) [0|3] ""  Vector__XXX
 SG_ ivi_fuelPortCapOpenCtrl : 3|2@0+ (1,0) [0|3] ""  Vector__XXX
 SG_ ivi_chrgPortCapOpenCtrl : 5|2@0+ (1,0) [0|3] ""  Vector__XXX
 SG_ ivi_antiTheftAlarmFormSet : 7|2@0+ (1,0) [0|3] ""  Vector__XXX
 SG_ ivi_approachingUnlockCtrl : 9|2@0+ (1,0) [0|3] ""  Vector__XXX
 SG_ ivi_awayLockCtrl : 11|2@0+ (1,0) [0|3] ""  Vector__XXX
 SG_ ivi_parkAutoCloseDRLCtrl : 13|2@0+ (1,0) [0|3] ""  Vector__XXX
 SG_ ivi_welcomeSetEnable : 15|2@0+ (1,0) [0|3] ""  Vector__XXX
 SG_ ivi_welcomeOnOffSet : 19|4@0+ (1,0) [0|15] ""  Vector__XXX
 SG_ ivi_followMeHomeSet : 22|3@0+ (1,0) [0|7] ""  Vector__XXX
 SG_ ivi_WiperMaintenanceCtrl : 25|2@0+ (1,0) [0|3] ""  Vector__XXX
 SG_ ivi_lockAutoCloseWinCtrl : 27|2@0+ (1,0) [0|3] ""  Vector__XXX
 SG_ IVI_Backlightadjust : 31|4@0+ (1,0) [0|10] ""  SWM
 SG_ IVI_Sunroof_HorizontalControl : 38|7@0+ (1,0) [0|100] "%"  Vector__XXX
 SG_ ivi_VehiclePowerOFF : 39|1@0+ (1,0) [0|1] ""  Vector__XXX
 SG_ ivi_sunroofGlassCmd : 42|3@0+ (1,0) [0|7] ""  Vector__XXX
 SG_ ivi_sunroofRollshadeCtrlSelect : 45|2@0+ (1,0) [0|3] ""  Vector__XXX
 SG_ ivi_tailgateCtrl : 47|2@0+ (1,0) [0|3] ""  Vector__XXX
 SG_ IVI_FLReadLightReq : 49|2@0+ (1,0) [0|3] ""  Vector__XXX
 SG_ IVI_FRReadLightReq : 51|2@0+ (1,0) [0|3] ""  Vector__XXX
 SG_ IVI_RLReadLightReq : 53|2@0+ (1,0) [0|3] ""  Vector__XXX
 SG_ IVI_RReadLightReq : 55|2@0+ (1,0) [0|3] ""  Vector__XXX
 SG_ IVI_ITLToplampReq : 57|2@0+ (1,0) [0|3] ""  Vector__XXX
 SG_ ivi_languageSet : 59|2@0+ (1,0) [0|3] ""  Vector__XXX
 SG_ ivi_unitSet : 61|2@0+ (1,0) [0|3] ""  Vector__XXX
 SG_ ivi_OutsideLockAlarmFormSet : 63|2@0+ (1,0) [0|3] ""  Vector__XXX

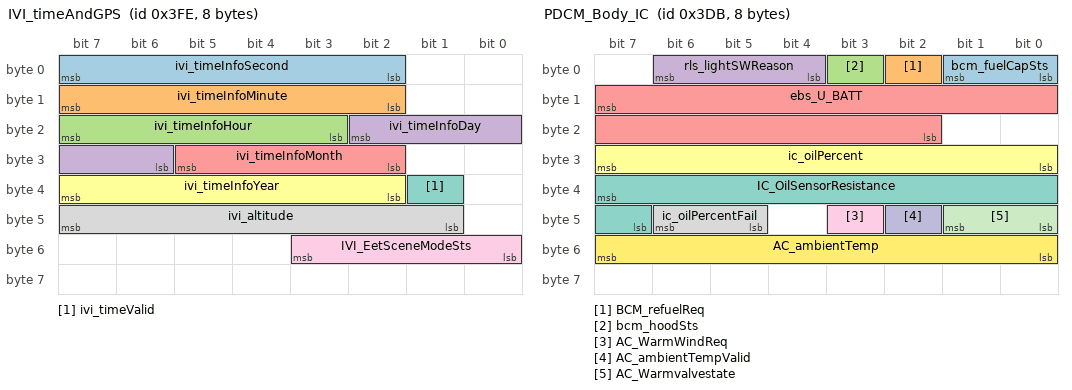
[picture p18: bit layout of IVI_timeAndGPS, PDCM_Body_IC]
BO_ 1022 IVI_timeAndGPS: 8 PDCM
 SG_ ivi_timeInfoSecond : 7|6@0+ (1,0) [0|59] ""  TCU,EMS,GCU,MCUF,MCUR
 SG_ ivi_timeInfoMinute : 15|6@0+ (1,0) [0|59] ""  TCU,EMS,GCU,MCUF,MCUR
 SG_ ivi_timeInfoHour : 23|5@0+ (1,0) [0|23] ""  TCU,EMS,GCU,MCUF,MCUR
 SG_ ivi_timeInfoDay : 18|5@0+ (1,0) [1|31] ""  TCU,EMS,GCU,MCUF,MCUR
 SG_ ivi_timeInfoMonth : 29|4@0+ (1,0) [1|12] ""  TCU,EMS,GCU,MCUF,MCUR
 SG_ ivi_timeInfoYear : 39|6@0+ (1,2000) [2000|2059] ""  TCU,EMS,GCU,MCUF,MCUR
 SG_ ivi_timeValid : 33|1@0+ (1,0) [0|1] ""  TCU,EMS,GCU,MCUF,MCUR
 SG_ ivi_altitude : 47|7@0+ (100,-100) [-100|8500] "degree"  GCU,MCUF
 SG_ IVI_EetSceneModeSts : 51|4@0+ (1,0) [0|15] ""  Vector__XXX

BO_ 987 PDCM_Body_IC: 8 PDCM
 SG_ bcm_fuelCapSts : 1|2@0+ (1,0) [0|3] ""  EMS,GCU,MCUF
 SG_ BCM_refuelReq : 2|1@0+ (1,0) [0|1] ""  EMS,GCU,MCUF
 SG_ bcm_hoodSts : 3|1@0+ (1,0) [0|1] ""  EMS,GCU,MCUF
 SG_ rls_lightSWReason : 6|3@0+ (1,0) [0|7] ""  GCU,MCUF,SWM
 SG_ ebs_U_BATT : 15|14@0+ (0.0009765625,3) [3|18] "V"  TCU,EMS,GCU,MCUF,MCUR,SWM
 SG_ ic_oilPercent : 31|8@0+ (1,0) [0|100] "%"  EMS,GCU,MCUF
 SG_ IC_OilSensorResistance : 39|9@0+ (1,0) [0|300] "Ω"  EMS,GCU,MCUF
 SG_ ic_oilPercentFail : 46|2@0+ (1,0) [0|3] ""  EMS,GCU,MCUF
 SG_ AC_WarmWindReq : 43|1@0+ (1,0) [0|1] "—"  EMS,GCU,MCUF
 SG_ AC_ambientTempValid : 42|1@0+ (1,0) [0|1] "bit"  TCU,EMS,GCU,MCUF
 SG_ AC_Warmvalvestate : 41|2@0+ (1,0) [0|3] "—"  EMS,GCU,MCUF
 SG_ AC_ambientTemp : 55|8@0+ (0.5,-40) [-40|85] "degreeC"  TCU,EMS,GCU,MCUF

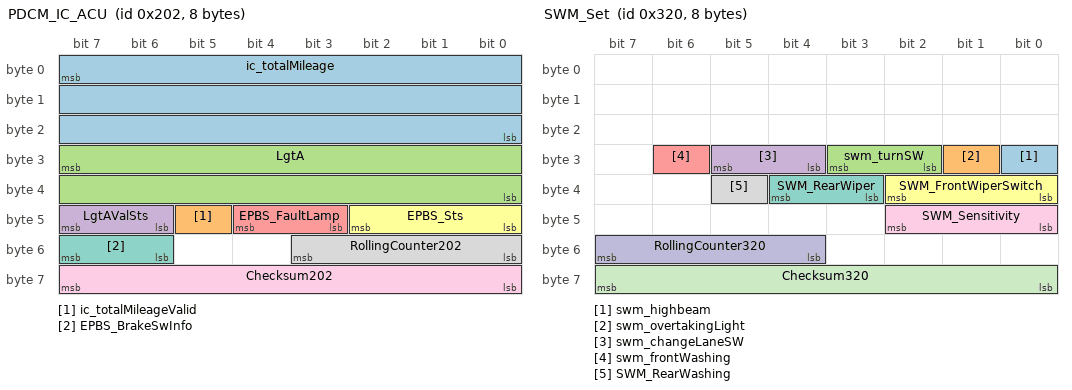
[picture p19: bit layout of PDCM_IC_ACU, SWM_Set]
BO_ 514 PDCM_IC_ACU: 8 PDCM
 SG_ ic_totalMileage : 7|24@0+ (0.1,0) [0|1677721.3] "km"  TCU,EMS,GCU,MCUF,MCUR,SWM
 SG_ ic_totalMileageValid : 45|1@0+ (1,0) [0|1] ""  TCU,EMS,GCU,MCUF,MCUR,SWM
 SG_ LgtA : 31|16@0+ (0.001,-2) [-2|2] "g"  TCU,GCU,MCUF,MCUR
 SG_ LgtAValSts : 47|2@0+ (1,0) [0|3] ""  TCU,GCU,MCUF,MCUR
 SG_ EPBS_FaultLamp : 44|2@0+ (1,0) [0|3] ""  TCU,GCU,MCUF
 SG_ EPBS_Sts : 42|3@0+ (1,0) [0|7] ""  TCU,EMS,GCU,MCUF,MCUR,SWM
 SG_ EPBS_BrakeSwInfo : 55|2@0+ (1,0) [0|3] ""  TCU,GCU,MCUF
 SG_ RollingCounter202 : 51|4@0+ (1,0) [0|15] ""  TCU,EMS,GCU,MCUF,MCUR,SWM
 SG_ Checksum202 : 63|8@0+ (1,0) [0|255] ""  TCU,EMS,GCU,MCUF,MCUR,SWM

BO_ 705 BCM_peps: 8 PDCM
 SG_ bcm_pepsPowerMode : 2|3@0+ (1,0) [0|7] ""  TCU,EMS,GCU,MCUF,MCUR,SWM
 SG_ bcm_IMMOReleaseIndication : 3|1@0+ (1,0) [0|1] ""  GCU,MCUF
 SG_ bcm_pepsKeyNotInCarInd : 4|1@0+ (1,0) [0|1] ""  GCU,MCUF
 SG_ bcm_keyValid : 6|2@0+ (1,0) [0|3] ""  GCU,MCUF
 SG_ bcm_pepsKeySerchFailInd : 7|1@0+ (1,0) [0|1] ""  GCU,MCUF
 SG_ bcm_pepsKeyCloserInd : 8|1@0+ (1,0) [0|1] ""  GCU,MCUF
 SG_ bcm_pepsFobLowBatWarning : 9|1@0+ (1,0) [0|1] ""  GCU,MCUF
 SG_ bcm_pepsPowerRelayErrWarning : 10|1@0+ (1,0) [0|1] ""  GCU,MCUF
 SG_ bcm_IndicationPressBrake : 12|1@0+ (1,0) [0|1] ""  GCU,MCUF
 SG_ bcm_LowFrequencyAntennaFault : 13|1@0+ (1,0) [0|1] ""  GCU,MCUF
 SG_ BCM_RainWinowCloseWarning : 14|1@0+ (1,0) [0|1] ""  GCU,MCUF
 SG_ BCM_KL15RelayReq : 15|1@0+ (1,0) [0|1] ""  Vector__XXX
 SG_ bcm_remoteMode : 17|2@0+ (1,0) [0|3] ""  TCU,EMS,GCU,MCUF,SWM
 SG_ bcm_ble_response : 19|2@0+ (1,0) [0|3] ""  EMS,GCU,MCUF
 SG_ BCM_RKEWindowCmd : 23|2@0+ (1,0) [0|3] ""  GCU,MCUF
 SG_ bcm_srSsAndWindowsEnable : 24|1@0+ (1,0) [0|1] ""  GCU,MCUF
 SG_ bcm_rke_fuelPortCapOpenCtrl : 26|2@0+ (1,0) [0|3] ""  GCU,MCUF
 SG_ bcm_pepsKeyInCarInd : 27|1@0+ (1,0) [0|1] ""  GCU,MCUF
 SG_ bcm_tbox_response : 29|2@0+ (1,0) [0|3] ""  EMS,GCU,MCUF
 SG_ bcm_approachingUnlockFedb : 31|2@0+ (1,0) [0|3] ""  GCU,MCUF
 SG_ bcm_12VBatterySOC : 39|8@0+ (1,0) [0|100] "%"  TCU,GCU,MCUF
 SG_ BCM_sunroofGlassCmd : 42|3@0+ (1,0) [0|7] ""  GCU,MCUF
 SG_ bcm_followMeHomeFedb : 45|3@0+ (1,0) [0|7] ""  GCU,MCUF
 SG_ bcm_awayLockFeedback : 47|2@0+ (1,0) [0|3] ""  GCU,MCUF
 SG_ bcm_PepsKeyIncarIndi : 49|2@0+ (1,0) [0|3] ""  GCU,MCUF
 SG_ bcm_GearPUnlockFeedback : 51|2@0+ (1,0) [0|3] ""  GCU,MCUF
 SG_ RollingCounter2C1 : 55|4@0+ (1,0) [0|15] ""  GCU,MCUF
 SG_ Checksum2C1 : 63|8@0+ (1,0) [0|255] ""  GCU,MCUF

BO_ 800 SWM_Set: 8 SWM
 SG_ swm_highbeam : 24|1@0+ (1,0) [0|1] ""  PDCM
 SG_ swm_overtakingLight : 25|1@0+ (1,0) [0|1] ""  PDCM
 SG_ swm_turnSW : 27|2@0+ (1,0) [0|3] ""  PDCM
 SG_ swm_changeLaneSW : 29|2@0+ (1,0) [0|3] ""  PDCM
 SG_ swm_frontWashing : 30|1@0+ (1,0) [0|1] ""  PDCM
 SG_ SWM_FrontWiperSwitch : 34|3@0+ (1,0) [0|7] ""  PDCM
 SG_ SWM_RearWiper : 36|2@0+ (1,0) [0|3] ""  PDCM
 SG_ SWM_RearWashing : 37|1@0+ (1,0) [0|1] ""  PDCM
 SG_ SWM_Sensitivity : 42|3@0+ (1,0) [0|7] ""  PDCM
 SG_ RollingCounter320 : 55|4@0+ (1,0) [0|15] ""  PDCM
 SG_ Checksum320 : 63|8@0+ (1,0) [0|255] ""  PDCM

BO_ 322 IPB5: 8 PDCM
 SG_ IPB_wheelSpeedFL : 7|13@0+ (0.05625,0) [0|270] "km/h"  TCU,EMS,GCU,MCUF
 SG_ IPB_wheelSpeedFLValid : 10|1@0+ (1,0) [0|1] ""  TCU,EMS,GCU,MCUF
 SG_ IPB_wheelSpeedFR : 23|13@0+ (0.05625,0) [0|270] "km/h"  TCU,EMS,GCU,MCUF
 SG_ IPB_wheelSpeedFRValid : 26|1@0+ (1,0) [0|1] ""  TCU,EMS,GCU,MCUF
 SG_ RollingCounter142 : 51|4@0+ (1,0) [0|15] ""  TCU,EMS,GCU,MCUF
 SG_ Checksum142 : 63|8@0+ (1,0) [0|255] ""  TCU,EMS,GCU,MCUF

BO_ 290 IPB4: 8 PDCM
 SG_ IPB_wheelSpeedRL : 7|13@0+ (0.05625,0) [0|270] "km/h"  TCU,EMS,GCU,MCUF
 SG_ IPB_wheelSpeedRLValid : 10|1@0+ (1,0) [0|1] ""  TCU,EMS,GCU,MCUF
 SG_ IPB_wheelSpeedRR : 23|13@0+ (0.05625,0) [0|270] "km/h"  TCU,EMS,GCU,MCUF
 SG_ IPB_wheelSpeedRRValid : 26|1@0+ (1,0) [0|1] ""  TCU,EMS,GCU,MCUF
 SG_ RollingCounter122 : 51|4@0+ (1,0) [0|15] ""  TCU,EMS,GCU,MCUF
 SG_ Checksum122 : 63|8@0+ (1,0) [0|255] ""  TCU,EMS,GCU,MCUF

BO_ 160 IPB7: 8 PDCM
 SG_ IPB_vehicleSpeed : 7|13@0+ (0.05625,0) [0|270] "km/h"  TCU,EMS,GCU,MCUF,MCUR,SWM
 SG_ IPB_vehicleSpeedValid : 10|1@0+ (1,0) [0|1] ""  TCU,EMS,GCU,MCUF,MCUR,SWM
 SG_ IPB_absFault : 9|1@0+ (1,0) [0|1] ""  GCU,MCUF
 SG_ IPB_absActive : 8|1@0+ (1,0) [0|1] ""  GCU,MCUF
 SG_ IPB_vdcActive : 16|1@0+ (1,0) [0|1] ""  GCU,MCUF
 SG_ IPB_tcsActive : 17|1@0+ (1,0) [0|1] ""  GCU,MCUF
 SG_ IPB_avhModeWSts : 19|2@0+ (1,0) [0|3] ""  GCU,MCUF
 SG_ IPB_avhAvailable : 20|1@0+ (1,0) [0|1] ""  GCU,MCUF
 SG_ IPB_cdpActive : 21|1@0+ (1,0) [0|1] ""  GCU,MCUF
 SG_ IPB_cdpAvailable : 22|1@0+ (1,0) [0|1] ""  GCU,MCUF
 SG_ IPB_hdcAvailable : 23|1@0+ (1,0) [0|1] ""  GCU,MCUF
 SG_ IPB_epbRequest : 25|2@0+ (1,0) [0|3] ""  GCU,MCUF
 SG_ IPB_vehicleStandstill : 27|2@0+ (1,0) [0|3] ""  GCU,MCUF
 SG_ IPB_vehicleStandstillValid : 28|1@0+ (1,0) [0|1] ""  GCU,MCUF
 SG_ IPB_ModeSts : 29|1@0+ (1,0) [0|1] ""  GCU,MCUF
 SG_ IPB_brakelightRequest : 30|1@0+ (1,0) [0|1] ""  GCU,MCUF
 SG_ IPB_hdcSts : 34|3@0+ (1,0) [0|3] ""  GCU,MCUF
 SG_ IPB_hhcActive : 35|1@0+ (1,0) [0|1] ""  GCU,MCUF
 SG_ IPB_hhcAvailable : 36|1@0+ (1,0) [0|1] ""  GCU,MCUF
 SG_ IPB_ebdFault : 37|1@0+ (1,0) [0|1] ""  GCU,MCUF
 SG_ IPB_ebd_active : 38|1@0+ (1,0) [0|1] ""  GCU,MCUF
 SG_ IPB_ESCoffSts : 39|1@0+ (1,0) [0|1] ""  GCU,MCUF
 SG_ IPB_escFault : 40|1@0+ (1,0) [0|1] ""  GCU,MCUF
 SG_ IPB_haz_active : 41|1@0+ (1,0) [0|1] ""  GCU,MCUF
 SG_ IPB_hazErrorSt : 42|1@0+ (1,0) [0|1] ""  GCU,MCUF
 SG_ IPB_hba_active : 43|1@0+ (1,0) [0|1] ""  GCU,MCUF
 SG_ IPB_dtcActive : 44|1@0+ (1,0) [0|1] ""  GCU,MCUF
 SG_ IPB_esclampdisplay : 46|2@0+ (1,0) [0|2] ""  GCU,MCUF
 SG_ IPB_BDWActive : 52|1@0+ (1,0) [0|1] ""  GCU,MCUF
 SG_ IPB_HRBActive : 53|1@0+ (1,0) [0|1] ""  GCU,MCUF
 SG_ RollingCounter0A0 : 51|4@0+ (1,0) [0|15] ""  TCU,EMS,GCU,MCUF,SWM
 SG_ Checksum0A0 : 63|8@0+ (1,0) [0|255] ""  TCU,EMS,GCU,MCUF,SWM

BO_ 179 PDCM_ACU_EPS: 8 PDCM
 SG_ acu_crashOutputStsValid : 3|2@0+ (1,0) [0|3] ""  TCU,EMS,GCU,MCUF,MCUR
 SG_ acu_crashOutputSts : 15|8@0+ (1,0) [0|255] ""  TCU,EMS,GCU,MCUF,MCUR
 SG_ eps_sasSteeringAngle : 23|16@0+ (0.1,-780) [-780|779.9] "deg"  TCU,GCU,MCUF
 SG_ eps_sasSteeringAngleValid : 39|1@0+ (1,0) [0|1] ""  TCU,GCU,MCUF
 SG_ RollingCounter0B3 : 51|4@0+ (1,0) [0|15] ""  TCU,EMS,GCU,MCUF,MCUR
 SG_ Checksum0B3 : 63|8@0+ (1,0) [0|255] ""  TCU,EMS,GCU,MCUF,MCUR

BO_ 1620 NM_PDCM_SPT2: 8 PDCM
 SG_ PDCM_SPT2_RMR : 8|1@0+ (1,0) [0|1] ""  TCU,MCUF,MCUR,SWM
 SG_ PDCM_SPT2_AWB : 12|1@0+ (1,0) [0|1] ""  TCU,MCUF,MCUR,SWM

BO_ 1587 NM_MCUF: 8 MCUF
 SG_ MCUF_RMR : 8|1@0+ (1,0) [0|1] ""  PDCM,TCU,MCUR,SWM
 SG_ MCUF_AWB : 12|1@0+ (1,0) [0|1] ""  PDCM,TCU,MCUR,SWM

BO_ 1586 NM_MCUR: 8 MCUR
 SG_ MCUR_RMR : 8|1@0+ (1,0) [0|1] ""  PDCM,TCU,MCUF,SWM
 SG_ MCUR_AWB : 12|1@0+ (1,0) [0|1] ""  PDCM,TCU,MCUF,SWM

BO_ 1561 NM_SWM: 8 SWM
 SG_ SWM_RMR : 8|1@0+ (1,0) [0|1] ""  PDCM,TCU,GCU,MCUF,MCUR
 SG_ SWM_AWB : 12|1@0+ (1,0) [0|1] ""  PDCM,TCU,GCU,MCUF,MCUR

BO_ 1596 NM_GCU: 8 GCU
 SG_ GCU_RMR : 8|1@0+ (1,0) [0|1] ""  PDCM,TCU,MCUF,MCUR,SWM
 SG_ GCU_AWB : 12|1@0+ (1,0) [0|1] ""  PDCM,TCU,MCUF,MCUR,SWM

BO_ 1427 GCU_Cal_Rx: 8 ExternalTool
 SG_ GCU_Cal_Rx : 7|64@0+ (1,0) [0|1] ""  GCU

BO_ 1436 GCU_Cal_Tx1: 8 GCU
 SG_ GCU_Cal_Tx1 : 7|64@0+ (1,0) [0|1] ""  ExternalTool

BO_ 1437 GCU_Cal_Tx2: 8 GCU
 SG_ GCU_Cal_Tx2 : 7|64@0+ (1,0) [0|1] ""  ExternalTool

BO_ 1438 GCU_Cal_Tx3: 8 GCU
 SG_ GCU_Cal_Tx3 : 7|64@0+ (1,0) [0|1] ""  ExternalTool

BO_ 1439 GCU_Cal_Tx4: 8 GCU
 SG_ GCU_Cal_Tx4 : 7|64@0+ (1,0) [0|1] ""  ExternalTool

BO_ 1455 GCU_Inner1: 8 GCU
 SG_ GCU_FalutInformation1 : 7|64@0+ (1,0) [0|1] ""  ExternalTool

BO_ 1426 GCU_Inner2: 8 GCU
 SG_ GCU_FalutInformation2 : 7|64@0+ (1,0) [0|1] ""  ExternalTool

BO_ 1488 MCUF_Cal_Rx: 8 ExternalTool
 SG_ MCUF_Cal_Rx : 7|64@0+ (1,0) [0|1] ""  MCUF

BO_ 1489 MCUF_Cal_Tx1: 8 MCUF
 SG_ MCUF_Cal_Tx1 : 7|64@0+ (1,0) [0|1] ""  ExternalTool

BO_ 1490 MCUF_Cal_Tx2: 8 MCUF
 SG_ MCUF_Cal_Tx2 : 7|64@0+ (1,0) [0|1] ""  ExternalTool

BO_ 1491 MCUF_Cal_Tx3: 8 MCUF
 SG_ MCUF_Cal_Tx3 : 7|64@0+ (1,0) [0|1] ""  ExternalTool

BO_ 1492 MCUF_Cal_Tx4: 8 MCUF
 SG_ MCUF_Cal_Tx4 : 7|64@0+ (1,0) [0|1] ""  ExternalTool

BO_ 1453 MCUF_Inner1: 8 MCUF
 SG_ MCUF_FalutInformation1 : 7|64@0+ (1,0) [0|1] ""  ExternalTool

BO_ 1454 MCUF_Inner2: 8 MCUF
 SG_ MCUF_FalutInformation2 : 7|64@0+ (1,0) [0|1] ""  ExternalTool

BO_ 2015 DiagReq_FUN: 8 PDCM
 SG_ FUN_DiagReq : 7|64@0+ (1,0) [0|1] ""  TCU,EMS,GCU,MCUF,MCUR,SWM

BO_ 2019 DiagReq_MCUF: 8 PDCM
 SG_ MCUF_DiagReq : 7|64@0+ (1,0) [0|1] ""  MCUF

BO_ 2027 DiagResp_MCUF: 8 MCUF
 SG_ MCUF_DiagResp : 7|64@0+ (1,0) [0|1] ""  PDCM

BO_ 2020 DiagReq_MCUR: 8 PDCM
 SG_ MCUR_DiagReq : 7|64@0+ (1,0) [0|1] ""  MCUR

BO_ 2028 DiagResp_MCUR: 8 MCUR
 SG_ MCUR_DiagResp : 7|64@0+ (1,0) [0|1] ""  PDCM

BO_ 2016 DiagReq_EMS: 8 PDCM
 SG_ EMS_DiagReq : 7|64@0+ (1,0) [0|1] ""  EMS

BO_ 2024 DiagResp_EMS: 8 EMS
 SG_ PEMS_DiagResp : 7|64@0+ (1,0) [0|1] ""  PDCM

BO_ 2022 DiagReq_GCU: 8 PDCM
 SG_ GCU_DiagReq : 7|64@0+ (1,0) [0|1] ""  GCU

BO_ 2030 DiagResp_GCU: 8 GCU
 SG_ GCU_DiagResp : 7|64@0+ (1,0) [0|1] ""  PDCM

BO_ 1817 DiagReq_SWM: 8 PDCM
 SG_ SWM_DiagReq : 7|64@0+ (1,0) [0|1] ""  SWM

BO_ 1945 DiagResp_SWM: 8 SWM
 SG_ SWM_DiagResp : 7|64@0+ (1,0) [0|1] ""  PDCM

BA_ "GenSigStartValue" SG_ 645 PDCM_SOC 2046;
BA_ "GenMsgCycleTime" BO_ 677 100;
BA_ "GenSigStartValue" SG_ 677 PDCM_AccelPedal_Position 1022;
BA_ "GenMsgCycleTime" BO_ 682 100;
BA_ "GenSigStartValue" SG_ 682 HVCM_ChargeSpeed 8190;
BA_ "GenSigStartValue" SG_ 682 HVCM_maxChargeSOC 100;
BA_ "GenSigStartValue" SG_ 682 HVCM_RestchargingTime 4094;
BA_ "GenSigStartValue" SG_ 682 HVCM_ChargeSpeed_Valid 2;
BA_ "GenSigStartValue" SG_ 682 HVCM_RestchargingTime_Valid 2;
BA_ "GenSigStartValue" SG_ 682 HVCM_ChargeState 30;
BA_ "GenMsgCycleTime" BO_ 1135 500;
BA_ "GenSigStartValue" SG_ 1135 TM_Temp_senser_1 510;
BA_ "GenSigStartValue" SG_ 1135 TM_Temp_senser_2 510;
BA_ "GenMsgCycleTime" BO_ 427 20;
BA_ "GenMsgCycleTime" BO_ 149 20;
BA_ "GenSigStartValue" SG_ 149 TCU_GearEngagementAvailable 1;
BA_ "GenMsgCycleTime" BO_ 151 20;
BA_ "GenSigStartValue" SG_ 151 TCU_MaxFrtMotPwr_Req 8190;
BA_ "GenSigStartValue" SG_ 151 TCU_MaxGCUPwr_Req 4094;
BA_ "GenMsgCycleTime" BO_ 817 100;
BA_ "GenMsgCycleTime" BO_ 131 10;
BA_ "GenSigStartValue" SG_ 131 EMS_StartAllowed 1;
BA_ "GenMsgCycleTime" BO_ 133 50;
BA_ "GenMsgCycleTime" BO_ 134 10;
BA_ "GenSigStartValue" SG_ 134 EMS_EngFlywh 8190;
BA_ "GenMsgCycleTime" BO_ 138 10;
BA_ "GenMsgCycleTime" BO_ 773 100;
BA_ "GenMsgCycleTime" BO_ 422 50;
BA_ "GenMsgCycleTime" BO_ 775 100;
BA_ "GenMsgCycleTime" BO_ 819 100;
BA_ "GenSigStartValue" SG_ 819 EMS_thermostat_valve 8;
BA_ "GenMsgCycleTime" BO_ 1132 500;
BA_ "GenSigStartValue" SG_ 1132 EMS_tankState 1;
BA_ "GenSigStartValue" SG_ 1132 EMS_GPFSootLoad 126;
BA_ "GenMsgCycleTime" BO_ 821 20;
BA_ "GenSigStartValue" SG_ 821 GCU_GeneratorDCCurrent 1000;
BA_ "GenSigStartValue" SG_ 821 GCU_GeneratorMaxSpd 14000;
BA_ "GenMsgCycleTime" BO_ 167 10;
BA_ "GenSigStartValue" SG_ 167 GCU_ActualTorque 3100;
BA_ "GenSigStartValue" SG_ 167 GCU_GeneratorSpd 200000;
BA_ "GenSigStartValue" SG_ 167 GCU_GeneratorSpdValid 1;
BA_ "GenSigStartValue" SG_ 167 GCU_State 1;
BA_ "GenSigStartValue" SG_ 167 GCU_MotorPower 1500;
BA_ "GenMsgCycleTime" BO_ 823 20;
BA_ "GenSigStartValue" SG_ 823 GCU_GeneratorMinNegativeTorque 3100;
BA_ "GenSigStartValue" SG_ 823 GCU_MinTorque_total 3100;
BA_ "GenMsgCycleTime" BO_ 864 100;
BA_ "GenMsgCycleTime" BO_ 1278 1000;
BA_ "GenMsgCycleTime" BO_ 82 100;
BA_ "GenMsgSendType" BO_ 476 3;
BA_ "GenMsgCycleTime" BO_ 476 100;
BA_ "GenMsgCycleTimeFast" BO_ 476 20;
BA_ "GenMsgNrOfRepetition" BO_ 476 3;
BA_ "GenMsgDelayTime" BO_ 476 20;
BA_ "GenSigSendType" SG_ 476 ivi_centralLockCtrl 4;
BA_ "GenSigSendType" SG_ 476 ivi_fuelPortCapOpenCtrl 4;
BA_ "GenSigSendType" SG_ 476 ivi_chrgPortCapOpenCtrl 4;
BA_ "GenSigSendType" SG_ 476 ivi_antiTheftAlarmFormSet 4;
BA_ "GenSigStartValue" SG_ 476 ivi_antiTheftAlarmFormSet 3;
BA_ "GenSigSendType" SG_ 476 ivi_approachingUnlockCtrl 4;
BA_ "GenSigSendType" SG_ 476 ivi_awayLockCtrl 4;
BA_ "GenSigSendType" SG_ 476 ivi_parkAutoCloseDRLCtrl 4;
BA_ "GenSigSendType" SG_ 476 ivi_welcomeSetEnable 4;
BA_ "GenSigSendType" SG_ 476 ivi_welcomeOnOffSet 4;
BA_ "GenSigSendType" SG_ 476 ivi_followMeHomeSet 4;
BA_ "GenSigSendType" SG_ 476 ivi_WiperMaintenanceCtrl 4;
BA_ "GenSigSendType" SG_ 476 ivi_lockAutoCloseWinCtrl 4;
BA_ "GenSigSendType" SG_ 476 IVI_Backlightadjust 4;
BA_ "GenSigSendType" SG_ 476 IVI_Sunroof_HorizontalControl 4;
BA_ "GenSigStartValue" SG_ 476 IVI_Sunroof_HorizontalControl 127;
BA_ "GenSigSendType" SG_ 476 ivi_VehiclePowerOFF 4;
BA_ "GenSigSendType" SG_ 476 ivi_sunroofGlassCmd 4;
BA_ "GenSigSendType" SG_ 476 ivi_sunroofRollshadeCtrlSelect 4;
BA_ "GenSigSendType" SG_ 476 ivi_tailgateCtrl 4;
BA_ "GenSigSendType" SG_ 476 IVI_FLReadLightReq 4;
BA_ "GenSigSendType" SG_ 476 IVI_FRReadLightReq 4;
BA_ "GenSigSendType" SG_ 476 IVI_RLReadLightReq 4;
BA_ "GenSigSendType" SG_ 476 IVI_RReadLightReq 4;
BA_ "GenSigSendType" SG_ 476 IVI_ITLToplampReq 4;
BA_ "GenSigSendType" SG_ 476 ivi_languageSet 4;
BA_ "GenSigStartValue" SG_ 476 ivi_languageSet 3;
BA_ "GenSigSendType" SG_ 476 ivi_unitSet 4;
BA_ "GenSigStartValue" SG_ 476 ivi_unitSet 2;
BA_ "GenSigSendType" SG_ 476 ivi_OutsideLockAlarmFormSet 4;
BA_ "GenMsgCycleTime" BO_ 1022 100;
BA_ "GenSigStartValue" SG_ 1022 ivi_timeInfoDay 1;
BA_ "GenSigStartValue" SG_ 1022 ivi_timeInfoMonth 1;
BA_ "GenSigStartValue" SG_ 1022 ivi_timeValid 1;
BA_ "GenSigStartValue" SG_ 1022 ivi_altitude 1;
BA_ "GenMsgCycleTime" BO_ 987 100;
BA_ "GenSigStartValue" SG_ 987 ebs_U_BATT 16383;
BA_ "GenSigStartValue" SG_ 987 ic_oilPercent 254;
BA_ "GenSigStartValue" SG_ 987 IC_OilSensorResistance 510;
BA_ "GenSigStartValue" SG_ 987 AC_ambientTemp 80;
BA_ "GenMsgCycleTime" BO_ 514 20;
BA_ "GenSigStartValue" SG_ 514 ic_totalMileage 16777214;
BA_ "GenSigStartValue" SG_ 514 LgtAValSts 3;
BA_ "GenMsgCycleTime" BO_ 705 100;
BA_ "GenMsgCycleTime" BO_ 800 100;
BA_ "GenSigStartValue" SG_ 800 SWM_FrontWiperSwitch 7;
BA_ "GenMsgCycleTime" BO_ 322 20;
BA_ "GenSigStartValue" SG_ 322 IPB_wheelSpeedFL 8190;
BA_ "GenSigStartValue" SG_ 322 IPB_wheelSpeedFR 8190;
BA_ "GenMsgCycleTime" BO_ 290 20;
BA_ "GenSigStartValue" SG_ 290 IPB_wheelSpeedRL 8190;
BA_ "GenSigStartValue" SG_ 290 IPB_wheelSpeedRR 8190;
BA_ "GenMsgCycleTime" BO_ 160 20;
BA_ "GenSigStartValue" SG_ 160 IPB_vehicleSpeed 8190;
BA_ "GenSigStartValue" SG_ 160 IPB_absFault 1;
BA_ "GenSigStartValue" SG_ 160 IPB_avhAvailable 1;
BA_ "GenSigStartValue" SG_ 160 IPB_ebdFault 1;
BA_ "GenSigStartValue" SG_ 160 IPB_ESCoffSts 1;
BA_ "GenSigStartValue" SG_ 160 IPB_escFault 1;
BA_ "GenMsgCycleTime" BO_ 179 10;
BA_ "GenSigStartValue" SG_ 179 acu_crashOutputStsValid 1;
BA_ "GenSigStartValue" SG_ 179 eps_sasSteeringAngle 65534;
BA_ "NmMessage" BO_ 1620 1;
BA_ "GenMsgSendType" BO_ 1620 1;
BA_ "GenSigSendType" SG_ 1620 PDCM_SPT2_RMR 2;
BA_ "GenSigSendType" SG_ 1620 PDCM_SPT2_AWB 2;
BA_ "NmMessage" BO_ 1587 1;
BA_ "GenMsgSendType" BO_ 1587 1;
BA_ "GenSigSendType" SG_ 1587 MCUF_RMR 2;
BA_ "GenSigSendType" SG_ 1587 MCUF_AWB 2;
BA_ "NmMessage" BO_ 1586 1;
BA_ "GenMsgSendType" BO_ 1586 1;
BA_ "GenSigSendType" SG_ 1586 MCUR_RMR 2;
BA_ "GenSigSendType" SG_ 1586 MCUR_AWB 2;
BA_ "NmMessage" BO_ 1561 1;
BA_ "GenMsgSendType" BO_ 1561 1;
BA_ "GenSigSendType" SG_ 1561 SWM_RMR 2;
BA_ "GenSigSendType" SG_ 1561 SWM_AWB 2;
BA_ "NmMessage" BO_ 1596 1;
BA_ "GenMsgSendType" BO_ 1596 1;
BA_ "GenSigSendType" SG_ 1596 GCU_RMR 2;
BA_ "GenSigSendType" SG_ 1596 GCU_AWB 2;
BA_ "GenMsgSendType" BO_ 1427 1;
BA_ "GenSigSendType" SG_ 1427 GCU_Cal_Rx 12;
BA_ "GenMsgSendType" BO_ 1436 1;
BA_ "GenSigSendType" SG_ 1436 GCU_Cal_Tx1 12;
BA_ "GenMsgSendType" BO_ 1437 1;
BA_ "GenSigSendType" SG_ 1437 GCU_Cal_Tx2 12;
BA_ "GenMsgSendType" BO_ 1438 1;
BA_ "GenSigSendType" SG_ 1438 GCU_Cal_Tx3 12;
BA_ "GenMsgSendType" BO_ 1439 1;
BA_ "GenSigSendType" SG_ 1439 GCU_Cal_Tx4 12;
BA_ "GenMsgCycleTime" BO_ 1455 100;
BA_ "GenSigSendType" SG_ 1455 GCU_FalutInformation1 12;
BA_ "GenMsgCycleTime" BO_ 1426 100;
BA_ "GenSigSendType" SG_ 1426 GCU_FalutInformation2 12;
BA_ "GenMsgSendType" BO_ 1488 1;
BA_ "GenSigSendType" SG_ 1488 MCUF_Cal_Rx 12;
BA_ "GenMsgSendType" BO_ 1489 1;
BA_ "GenSigSendType" SG_ 1489 MCUF_Cal_Tx1 12;
BA_ "GenMsgSendType" BO_ 1490 1;
BA_ "GenSigSendType" SG_ 1490 MCUF_Cal_Tx2 12;
BA_ "GenMsgSendType" BO_ 1491 1;
BA_ "GenSigSendType" SG_ 1491 MCUF_Cal_Tx3 12;
BA_ "GenMsgSendType" BO_ 1492 1;
BA_ "GenSigSendType" SG_ 1492 MCUF_Cal_Tx4 12;
BA_ "GenMsgCycleTime" BO_ 1453 100;
BA_ "GenSigSendType" SG_ 1453 MCUF_FalutInformation1 12;
BA_ "GenMsgCycleTime" BO_ 1454 100;
BA_ "GenSigSendType" SG_ 1454 MCUF_FalutInformation2 12;
BA_ "DiagState" BO_ 2015 1;
BA_ "GenMsgSendType" BO_ 2015 1;
BA_ "GenSigSendType" SG_ 2015 FUN_DiagReq 2;
BA_ "GenMsgSendType" BO_ 2019 1;
BA_ "GenSigSendType" SG_ 2019 MCUF_DiagReq 2;
BA_ "GenMsgSendType" BO_ 2027 1;
BA_ "GenSigSendType" SG_ 2027 MCUF_DiagResp 2;
BA_ "GenMsgSendType" BO_ 2020 1;
BA_ "GenSigSendType" SG_ 2020 MCUR_DiagReq 2;
BA_ "GenMsgSendType" BO_ 2028 1;
BA_ "GenSigSendType" SG_ 2028 MCUR_DiagResp 2;
BA_ "GenMsgSendType" BO_ 2016 1;
BA_ "GenSigSendType" SG_ 2016 EMS_DiagReq 2;
BA_ "GenMsgSendType" BO_ 2024 1;
BA_ "GenSigSendType" SG_ 2024 PEMS_DiagResp 2;
BA_ "GenMsgSendType" BO_ 2022 1;
BA_ "GenSigSendType" SG_ 2022 GCU_DiagReq 2;
BA_ "GenMsgSendType" BO_ 2030 1;
BA_ "GenSigSendType" SG_ 2030 GCU_DiagResp 2;
BA_ "GenMsgSendType" BO_ 1817 1;
BA_ "GenSigSendType" SG_ 1817 SWM_DiagReq 2;
BA_ "GenMsgSendType" BO_ 1945 1;
BA_ "GenSigSendType" SG_ 1945 SWM_DiagResp 2;
VAL_ 161 MCUF_ActualTorque 16383 "Invalid" ;
VAL_ 161 MCUF_MotorSpdValid 1 "Valid" 0 "Invalid" ;
VAL_ 161 MCUF_MotorSpd 65535 "Invalid" ;
VAL_ 161 MCUF_SelfheatingAllow 1 "允许" 0 "不允许" ;
VAL_ 161 MCUF_SelfheatingMode 1 "电机已开启自加热控制" 0 "未运行" ;
VAL_ 162 MCUF_AS_Activ 1 "Anti-Surge_Activ" 0 "Anti-Surge_InActiv" ;
VAL_ 162 MCUF_Fault_ASC 1 "ASC_Activ" 0 "ASC_InActiv" ;
VAL_ 162 MCUF_Fault_ShutOff_HV_Req 1 "Fault_req" 0 "Normal" ;
VAL_ 162 MCUF_TMReq_ASC 1 "Request" 0 "No request" ;
VAL_ 162 MCUF_Actual_Voltage 4095 "Invalid" ;
VAL_ 162 MCUF_Current_HV 4095 "Invalid" ;
VAL_ 162 MCUF_State 6 "discharge" 5 "fault" 4 "speedctrl" 3 "torquectrl" 2 "standby" 1 "initial" 0 "reserved" ;
VAL_ 164 MCUF_BusCurrent 2047 "Invalid" ;
VAL_ 164 MCUF_BusFreq 4095 "Invalid" ;
VAL_ 849 MCUF_ControllerTemp 255 "Invalid" ;
VAL_ 849 MCUF_MotorTemp 255 "Invalid" ;
VAL_ 849 MCUF_Motor_Current_Phase_A 4095 "Invalid" ;
VAL_ 849 MCUF_Motor_Current_Phase_B 4095 "Invalid" ;
VAL_ 849 MCUF_Motor_Current_Phase_C 4095 "Invalid" ;
VAL_ 789 MCUF_Status_ActiveDischarge 1 "active" 0 "incative" ;
VAL_ 789 MCUF_Fault_ActiveDischarge 1 "Fault" 0 "Normal" ;
VAL_ 789 MCUF_Fault_PowerDerating 1 "Fault_Derating" 0 "Normal" ;
VAL_ 789 MCUF_FaultLamp_Req 3 "Reserve" 2 "Red-LED request" 1 "Yellow-LED request" 0 "No Request" ;
VAL_ 789 MCUF_OBD_Lamp_Req 3 "INVALID" 2 "RESERVED" 1 "ON" 0 "OFF" ;
VAL_ 789 MCUF_MotorStatus 7 "无效" 6 "异常" 5 "预留" 4 "预留" 3 "关闭" 2 "发电" 1 "耗电" 0 "准备状态" ;
VAL_ 787 MCUF_UdFreq 2047 "Invalid" ;
VAL_ 787 MCUF_UdVolt 16383 "Invalid" ;
VAL_ 1045 MCUF_RTM_WarnComm 3 "Level_3_Fault" 2 "Level_2_Fault" 1 "Level_1_Fault" 0 "Init" ;
VAL_ 1045 MCUF_RTM_OverTemp_EM 3 "Level_3_Fault" 2 "Level_2_Fault" 1 "Level_1_Fault" 0 "Init" ;
VAL_ 1045 MCUF_RTM_OverTemp_MCU 3 "Level_3_Fault" 2 "Level_2_Fault" 1 "Level_1_Fault" 0 "Init" ;
VAL_ 1045 MCUF_RTM_OverSpeed 3 "Level_3_Fault" 2 "Level_2_Fault" 1 "Level_1_Fault" 0 "Init" ;
VAL_ 1045 MCUF_RTM_OverCurrent 3 "Level_3_Fault" 2 "Level_2_Fault" 1 "Level_1_Fault" 0 "Init" ;
VAL_ 1045 MCUF_Derating_OverTemp 1 "Derating_OT" 0 "No Derating" ;
VAL_ 1045 MCUF_HV_Voltg_Free 3 "Fault(f.e. Fault of sensor)" 2 "HV-System is not voltage free(U≥20V)" 1 "HV-system is voltage free(U＜20V)" 0 "init" ;
VAL_ 166 MCUR_ActualTorque 16383 "Invalid" ;
VAL_ 166 MCUR_MotorSpdValid 1 "Valid" 0 "Invalid" ;
VAL_ 166 MCUR_MotorSpd 65535 "Invalid" ;
VAL_ 166 MCUR_SelfheatingAllow 1 "允许" 0 "不允许" ;
VAL_ 166 MCUR_SelfheatingMode 1 "电机已开启自加热控制" 0 "未运行" ;
VAL_ 163 MCUR_AS_Activ 1 "Anti-Surge_Activ" 0 "Anti-Surge_InActiv" ;
VAL_ 163 MCUR_Fault_ASC 1 "ASC_Activ" 0 "ASC_InActiv" ;
VAL_ 163 MCUR_Fault_ShutOff_HV_Req 1 "Fault_req" 0 "Normal" ;
VAL_ 163 MCUR_TMReq_ASC 1 "Request" 0 "No request" ;
VAL_ 163 MCUR_Actual_Voltage 4095 "Invalid" ;
VAL_ 163 MCUR_State 6 "discharge" 5 "fault" 4 "speedctrl" 3 "torquectrl" 2 "standby" 1 "initial" 0 "reserved" ;
VAL_ 785 MCUR_BusCurrent 2047 "Invalid" ;
VAL_ 785 MCUR_BusFreq 4095 "Invalid" ;
VAL_ 850 MCUR_ControllerTemp 255 "Invalid" ;
VAL_ 850 MCUR_MotorTemp 255 "Invalid" ;
VAL_ 850 MCUR_Motor_Current_Phase_A 4095 "Invalid" ;
VAL_ 850 MCUR_Motor_Current_Phase_B 4095 "Invalid" ;
VAL_ 850 MCUR_Motor_Current_Phase_C 4095 "Invalid" ;
VAL_ 790 MCUR_Status_ActiveDischarge 1 "active" 0 "incative" ;
VAL_ 790 MCUR_Fault_ActiveDischarge 1 "Fault" 0 "Normal" ;
VAL_ 790 MCUR_Fault_PowerDerating 1 "Fault_Derating" 0 "Normal" ;
VAL_ 790 MCUR_FaultLamp_Req 3 "Reserve" 2 "Red-LED request" 1 "Yellow-LED request" 0 "No Request" ;
VAL_ 790 MCUR_OBD_Lamp_Req 3 "INVALID" 2 "RESERVED" 1 "ON" 0 "OFF" ;
VAL_ 790 MCUR_MotorStatus 7 "无效" 6 "异常" 5 "预留" 4 "预留" 3 "关闭" 2 "发电" 1 "耗电" 0 "准备状态" ;
VAL_ 786 MCUR_UdFreq 2047 "Invalid" ;
VAL_ 786 MCUR_UdVolt 16383 "Invalid" ;
VAL_ 1046 MCUR_RTM_WarnComm 3 "Level_3_Fault" 2 "Level_2_Fault" 1 "Level_1_Fault" 0 "Init" ;
VAL_ 1046 MCUR_RTM_OverTemp_EM 3 "Level_3_Fault" 2 "Level_2_Fault" 1 "Level_1_Fault" 0 "Init" ;
VAL_ 1046 MCUR_RTM_OverTemp_MCU 3 "Level_3_Fault" 2 "Level_2_Fault" 1 "Level_1_Fault" 0 "Init" ;
VAL_ 1046 MCUR_RTM_OverSpeed 3 "Level_3_Fault" 2 "Level_2_Fault" 1 "Level_1_Fault" 0 "Init" ;
VAL_ 1046 MCUR_RTM_OverCurrent 3 "Level_3_Fault" 2 "Level_2_Fault" 1 "Level_1_Fault" 0 "Init" ;
VAL_ 1046 MCUR_Derating_OverTemp 1 "Derating_OT" 0 "No Derating" ;
VAL_ 1046 MCUR_HV_Voltg_Free 3 "Fault(f.e. Fault of sensor)" 2 "HV-System is not voltage free(U≥20V)" 1 "HV-system is voltage free(U＜20V)" 0 "init" ;
VAL_ 777 swm_epb_switch 1 "Applied" 0 "No Active" ;
VAL_ 777 swm_epb_switch_status 1 "Invalid" 0 "Valid" ;
VAL_ 777 gsm_gearSelectorPos 7 "RESERVE" 6 "RESERVE" 5 "RESERVE" 4 "NO_TARGET" 3 "D" 2 "N" 1 "R" 0 "P" ;
VAL_ 777 gsm_gearSelectorPosValid 1 "Valid" 0 "Invalid" ;
VAL_ 777 gsm_faultLevel 3 "FAULT LEVEL 3" 2 "FAULT LEVEL 2" 1 "FAULT LEVEL 1" 0 "NORMAL" ;
VAL_ 777 gsm_warnInformation 7 "Reserved" 6 "Reserved" 5 "Reserved" 4 "Knob is clamp（换挡杆卡滞）" 3 "Unlock Button Invalid  (图片及文字提示)" 2 "P Button Invalid  (图片及文字提示)" 1 "please press unlock buttton (图片及文字提示)" 0 "no warn" ;
VAL_ 777 gsm_lever_position 7 "Reserved" 6 "Reserved" 5 "Reserved" 4 "down down" 3 "down" 2 "up up" 1 "up" 0 "center" ;
VAL_ 777 SWM_PBtnSts 3 "reserved" 2 "reserved" 1 "Pressed" 0 "Not pressed" ;
VAL_ 660 GSM_OBD_F000_BusOFF_Sts 3 "Reserved" 2 "Diagnostic Failed" 1 "Diagnostic Passed" 0 "Diagnostic not finished" ;
VAL_ 660 GSM_OBD_F001_BatVolHigh_Sts 3 "Reserved" 2 "Diagnostic Failed" 1 "Diagnostic Passed" 0 "Diagnostic not finished" ;
VAL_ 660 GSM_OBD_F002_BatVolLow_Sts 3 "Reserved" 2 "Diagnostic Failed" 1 "Diagnostic Passed" 0 "Diagnostic not finished" ;
VAL_ 660 GSM_OBD_F003_KnobClamp_Sts 3 "Reserved" 2 "Diagnostic Failed" 1 "Diagnostic Passed" 0 "Diagnostic not finished" ;
VAL_ 660 GSM_OBD_F004_SensorFlt_Sts 3 "Reserved" 2 "Diagnostic Failed" 1 "Diagnostic Passed" 0 "Diagnostic not finished" ;
VAL_ 660 GSM_OBD_F005_HALLAgMagicOut_Sts 3 "Reserved" 2 "Diagnostic Failed" 1 "Diagnostic Passed" 0 "Diagnostic not finished" ;
VAL_ 660 GSM_OBD_F006_HALLChipSpiComFlt_Sts 3 "Reserved" 2 "Diagnostic Failed" 1 "Diagnostic Passed" 0 "Diagnostic not finished" ;
VAL_ 660 GSM_OBD_F007_DblPBtnDif_Sts 3 "Reserved" 2 "Diagnostic Failed" 1 "Diagnostic Passed" 0 "Diagnostic not finished" ;
VAL_ 660 GSM_OBD_F008_ParkBtnAdheFlt_Sts 3 "Reserved" 2 "Diagnostic Failed" 1 "Diagnostic Passed" 0 "Diagnostic not finished" ;
VAL_ 660 GSM_OBD_F009_ParkBtnCircFlt_Sts 3 "Reserved" 2 "Diagnostic Failed" 1 "Diagnostic Passed" 0 "Diagnostic not finished" ;
VAL_ 660 GSM_OBD_F00A_UnlckBtnAdheFlt_Sts 3 "Reserved" 2 "Diagnostic Failed" 1 "Diagnostic Passed" 0 "Diagnostic not finished" ;
VAL_ 660 GSM_OBD_F00B_UnlckBtnCircFlt_Sts 3 "Reserved" 2 "Diagnostic Failed" 1 "Diagnostic Passed" 0 "Diagnostic not finished" ;
VAL_ 660 GSM_OBD_F00C_GlbTimeoutPT_Sts 3 "Reserved" 2 "Diagnostic Failed" 1 "Diagnostic Passed" 0 "Diagnostic not finished" ;
VAL_ 660 GSM_OBD_F00D_BackLiDriverFlt_Sts 3 "Reserved" 2 "Diagnostic Failed" 1 "Diagnostic Passed" 0 "Diagnostic not finished" ;
VAL_ 660 GSM_OBD_F00E_GearIndiDriverFlt_Sts 3 "Reserved" 2 "Diagnostic Failed" 1 "Diagnostic Passed" 0 "Diagnostic not finished" ;
VAL_ 660 GSM_OBD_F00F_RAM_Flt_Sts 3 "Reserved" 2 "Diagnostic Failed" 1 "Diagnostic Passed" 0 "Diagnostic not finished" ;
VAL_ 660 GSM_OBD_F010_ROMFlt_Sts 3 "Reserved" 2 "Diagnostic Failed" 1 "Diagnostic Passed" 0 "Diagnostic not finished" ;
VAL_ 660 GSM_OBD_F011_EEPROMFlt_Sts 3 "Reserved" 2 "Diagnostic Failed" 1 "Diagnostic Passed" 0 "Diagnostic not finished" ;
VAL_ 660 GSM_OBD_F012_WdgFlt_Sts 3 "Reserved" 2 "Diagnostic Failed" 1 "Diagnostic Passed" 0 "Diagnostic not finished" ;
VAL_ 660 GSM_OBD_F013_LostComWithPDCM_Sts 3 "Reserved" 2 "Diagnostic Failed" 1 "Diagnostic Passed" 0 "Diagnostic not finished" ;
VAL_ 660 GSM_OBD_F014_SigInvldPDCM10_Sts 3 "Reserved" 2 "Diagnostic Failed" 1 "Diagnostic Passed" 0 "Diagnostic not finished" ;
VAL_ 660 GSM_OBD_F015_SigInvldWithIC_Sts 3 "Reserved" 2 "Diagnostic Failed" 1 "Diagnostic Passed" 0 "Diagnostic not finished" ;
VAL_ 660 GSM_OBD_F016_LostComWithIVI_Sts 3 "Reserved" 2 "Diagnostic Failed" 1 "Diagnostic Passed" 0 "Diagnostic not finished" ;
VAL_ 660 GSM_OBD_F017_SigInvldWithIVI_Sts 3 "Reserved" 2 "Diagnostic Failed" 1 "Diagnostic Passed" 0 "Diagnostic not finished" ;
VAL_ 660 GSM_OBD_F018_LostComWithBCM_Sts 3 "Reserved" 2 "Diagnostic Failed" 1 "Diagnostic Passed" 0 "Diagnostic not finished" ;
VAL_ 660 GSM_OBD_F019_SigInvldWithBCM_Sts 3 "Reserved" 2 "Diagnostic Failed" 1 "Diagnostic Passed" 0 "Diagnostic not finished" ;
VAL_ 660 GSM_OBD_F01A_LostComWithIPB_Sts 3 "Reserved" 2 "Diagnostic Failed" 1 "Diagnostic Passed" 0 "Diagnostic not finished" ;
VAL_ 660 GSM_OBD_F01B_SigInvldWithIPB7_Sts 3 "Reserved" 2 "Diagnostic Failed" 1 "Diagnostic Passed" 0 "Diagnostic not finished" ;
VAL_ 660 GSM_OBD_FaultClrsts 1 "Complete" 0 "NO complete" ;
VAL_ 660 GSM_OBD_F01C_LostComWithIC_Sts 3 "Reserved" 2 "Diagnostic Failed" 1 "Diagnostic Passed" 0 "Diagnostic not finished" ;
VAL_ 712 PDCM_actualGearValid 1 "VALID" 0 "INVALID" ;
VAL_ 712 PDCM_targetGearValid 1 "VALID" 0 "INVALID" ;
VAL_ 712 PDCM_actualGear 3 "D" 2 "N" 1 "R" 0 "P" ;
VAL_ 712 PDCM_targetGear 3 "D" 2 "N" 1 "R" 0 "P" ;
VAL_ 712 PDCM_AccelPedal_Status 1023 "Invalid" ;
VAL_ 712 PDCM_BrakePedal_Valid 1 "Valid" 0 "Invalid" ;
VAL_ 712 PDCM_BrakePedal_Status 1 "Pressed" 0 "not_Pressed" ;
VAL_ 712 PDCM_BrakePedal_PressRemind 1 "Warning" 0 "Normal" ;
VAL_ 712 PDCM_AccelPedal_Valid 1 "Valid" 0 "Invalid" ;
VAL_ 712 PDCM_APADrvAst_allow 1 "APA allow" 0 "Not allow" ;
VAL_ 712 PDCM_ACCDrvAst_allow 1 "ACC allow" 0 "Not allow" ;
VAL_ 712 PDCM_Gear_intervention 1 "Driver Request Intervention" 0 "No Intervention" ;
VAL_ 712 PDCM_DriveReady 3 "Fault" 2 "Ready_Romote" 1 "Ready_Local" 0 "Not_Ready" ;
VAL_ 712 PDCM_EVMode_Status 2 "EV_Mode_inactive" 1 "EV_Mode_active" 0 "Init" ;
VAL_ 712 PDCM_VehicleSpeed 511 "Invalid" ;
VAL_ 712 PDCM_driveMode 7 "RESERVED" 6 "RESERVED" 5 "RESERVED" 4 "RESERVED" 3 "SNOW" 2 "SPORT" 1 "COMFORT" 0 "ECO" ;
VAL_ 712 PDCM_driveMode_HW 7 "预留" 6 "预留" 5 "all road郊游" 4 "individual个性化" 3 "snow" 2 "sport" 1 "comfort" 0 "eco" ;
VAL_ 712 PDCM_authenticationResult 3 "RESERVE_AUTH" 2 "AUTH_SUCCESS" 1 "AUTH_FAILED" 0 "UINITIAL_OR_AUTH_INPROGRESS" ;
VAL_ 712 HV_Network_active 1 "active" 0 "inactive" ;
VAL_ 712 HV_Network_Fault 1 "Fault" 0 "Normal" ;
VAL_ 178 PDCM_MCUF_AntiJerk 1 "active" 0 "inactive" ;
VAL_ 178 PDCM_MCUF_TorqueReq 16383 "Invalid" ;
VAL_ 178 PDCM_MCUF_SpeedReq 4095 "Invalid" ;
VAL_ 178 PDCM_SelfheatingReq_MCUF 1 "开启自加热命令" 0 "不开启" ;
VAL_ 178 HVCO_MCUF_StateCmd 14 "Discharge" 5 "SpeedCtrl" 4 "TrqCtrl" 3 "Reserve" 2 "Standby" 1 "intial" 0 "off" ;
VAL_ 181 PDCM_MCUR_AntiJerk 1 "active" 0 "inactive" ;
VAL_ 181 PDCM_MCUR_TorqueReq 16383 "Invalid" ;
VAL_ 181 PDCM_MCUR_SpeedReq 4095 "Invalid" ;
VAL_ 181 PDCM_SelfheatingReq_MCUR 1 "开启自加热命令" 0 "不开启" ;
VAL_ 181 HVCO_MCUR_StateCmd 14 "Discharge" 5 "SpeedCtrl" 4 "TrqCtrl" 3 "Reserve" 2 "Standby" 1 "intial" 0 "off" ;
VAL_ 183 PDCM_engFlywhTrqFastCmd 8191 "Invalid" ;
VAL_ 183 PDCM_fuelInjectInhibitCmd 1 "INJECTION NOT ENABLE" 0 "INJECTION ENABLE" ;
VAL_ 183 PDCM_engStopCmd 1 "STOP" 0 "NO_STOP" ;
VAL_ 183 PDCM_engFlywhTrqSlowCmd 8191 "Invalid" ;
VAL_ 183 PDCM_IgAglRls 1 "Active" 0 "Deactive" ;
VAL_ 183 PDCM_RampEngRq 1 "Enable(Ramp)" 0 "Disable(No Ramp Request)" ;
VAL_ 183 PDCM_FuelCutOff 1 "Enable" 0 "Disable" ;
VAL_ 183 PDCM_engStartMode 3 "NONE" 2 "IGN_START" 1 "NORMAL_START" 0 "NO_START" ;
VAL_ 183 PDCM_EngIdleReq 2 "Invalid" 1 "Request" 0 "No request" ;
VAL_ 183 PDCM_engStartCmd 1 "START" 0 "NO_START" ;
VAL_ 185 PDCM_ClutchCommandTransferTorque 4095 "Invalid" ;
VAL_ 185 PDCM_ClutchCommand 7 "reserved" 6 "reserved" 5 "reserved" 4 "reserved" 3 "reserved" 2 "Clutch Close" 1 "Clutch prepare" 0 "Clutch open" ;
VAL_ 185 HVCO_ActiveDischarge_Req 1 "Request" 0 "No_Reqest" ;
VAL_ 185 HVCO_EmergencyShutdown_Req 3 "Init" 1 "Request" 0 "NO_Req" ;
VAL_ 185 PDCM_Max_Voltage 1023 "Invalid" ;
VAL_ 185 PDCM_Min_Voltage 1023 "Invalid" ;
VAL_ 185 PDCM_DrivingCycle 1 "激活" 0 "没有激活" ;
VAL_ 185 PDCM_Dcy_valid 1 "Valid" 0 "Invalid" ;
VAL_ 186 PDCM_GCU_Torque_Ref 4094 "Init" ;
VAL_ 186 HVCO_GCU_StateCmd 14 "Discharge" 5 "SpeedCtrl" 4 "TrqCtrl" 3 "Reserve" 2 "Standby" 1 "intial" 0 "off" ;
VAL_ 983 PDCM_MCUF_MaxPower_D 8191 "Invalid" ;
VAL_ 983 PDCM_MCUF_MaxPower_G 4095 "Invalid" ;
VAL_ 983 PDCM_MCUR_MaxPower_D 8191 "Invalid" ;
VAL_ 983 PDCM_MCUR_MaxPower_G 4095 "Invalid" ;
VAL_ 854 PDCM_SelfheatingMode 1 "整车运行自加热中" 0 "未运行" ;
VAL_ 854 PDCM_MainCoolPumpReqDC 127 "Invalid" ;
VAL_ 645 HVEM_HV_Req 1 "Request" 0 "No_Req" ;
VAL_ 645 HVEM_Power_Aux 511 "Fault" 510 "Init" ;
VAL_ 645 HVEM_Current_HVAux 4095 "Fault" 4094 "Init" ;
VAL_ 645 PDCM_SOC 2047 "Fault" 2046 "init" ;
VAL_ 645 PDCM_KL15DelayAllow 1 "allow" 0 "not allow" ;
VAL_ 677 PDCM_OBD_WarmCycleSts 1 "ACHIEVED" 0 "NOT_ACHIEVED" ;
VAL_ 677 PDCM_OBD_DenoGeneral 1 "active" 0 "inactive" ;
VAL_ 677 PDCM_OBD_DenoGenValid 1 "Valid" 0 "Invalid" ;
VAL_ 677 PDCM_OBD_DenoSpecial 1 "active" 0 "inactive" ;
VAL_ 677 PDCM_OBD_DenoSpecValid 1 "Valid" 0 "Invalid" ;
VAL_ 677 PDCM_OBD_PDTCClrSts 1 "active" 0 "inactive" ;
VAL_ 677 PDCM_OBD_FaultClrInhibit 1 "Inhibit" 0 "No Inhibit" ;
VAL_ 677 PDCM_OBD_FaultClrReq 1 "Active" 0 "NO Request" ;
VAL_ 677 PDCM_AccelPedal_Position 1023 "Invalid" ;
VAL_ 677 PDCM_CatHeatAllow 1 "Allow 允许催化器加热" 0 "NotAllow 不允许催化器加热" ;
VAL_ 677 PDCM_GPFUdsRgnAcv 1 "GPF UDS再生激活状态" 0 "GPF UDS再生未激活" ;
VAL_ 682 HVCM_ChargeSpeed 8191 "Invalid" ;
VAL_ 682 HVCM_ChargeSpeed_Unit 2 "km_per_hour" 1 "km_per_Minute" 0 "Init" ;
VAL_ 682 HVCM_maxChargeSOC 255 "Invalid" 254 "No Request" ;
VAL_ 682 HVCM_RestchargingTime 4095 "Fault" 4094 "Init" 4093 "充电即将完成" 4092 "计算中" ;
VAL_ 682 HVCM_ChargeSpeed_Valid 2 "invalid" 1 "valid" 0 "caculating" ;
VAL_ 682 HVCM_RestchargingTime_Valid 2 "invalid" 1 "valid" 0 "caculating" ;
VAL_ 682 HVCM_VehicleHold_Req 2 "Reserve" 1 "Vehicle_Hold_Req" 0 "No_Request" ;
VAL_ 682 HVCM_AWC_AssemblyStatus 3 "Fault" 2 "Assemble" 1 "not_assemble" 0 "Init" ;
VAL_ 682 HVCM_ChargeState 31 "Fault" 30 "Init" 12 "Fault_ChargingStation" 11 "Fualt_ChargingSystem" 10 "Fualt_PlugLock" 9 "No_AC_Voltage" 8 "Reserve" 7 "Timer_Charging_waiting" 6 "V2L DisCharging" 5 "immeidately_Charging_active" 4 "Timer_Charging_active" 3 "Battery Pre-Heating active" 2 "Reserve" 1 "Charing_Finished" 0 "OFF" ;
VAL_ 682 HVCM_Charge_Req 7 "Reserve" 6 "DC_AND_AWC_Request" 5 "AC_AND_AWC_Request" 4 "AWC_Request" 3 "AC_AND_DC_Charge_Request" 2 "DC_Charge_Request" 1 "AC_Charge_request" 0 "No_Request" ;
VAL_ 682 HVCM_ChargePlugUnlock_Req 1 "Request_plug_Unlock" 0 "No_Request" ;
VAL_ 682 HVCM_HV_Req 1 "HV_Request" 0 "No Request" ;
VAL_ 1135 TM_Temp_senser_1 511 "Invalid" ;
VAL_ 1135 TM_Temp_senser_2 511 "Invalid" ;
VAL_ 427 PDCM_MCURTqLimMin 511 "Invalid" ;
VAL_ 427 PDCM_MCURTqLimMax 511 "Invalid" ;
VAL_ 427 PDCM_MCURTqRateLimMin 511 "Invalid" ;
VAL_ 427 PDCM_MCURTqRateLimMax 511 "Invalid" ;
VAL_ 427 PDCM_MCURTqUnloadRate 511 "Invalid" ;
VAL_ 427 PDCM_MCURTqUnloadEna 3 "reserved" 2 "reserved" 1 "Enable" 0 "Disable" ;
VAL_ 427 PDCM_MCURTarSpdSvValid 1 "valid" 0 "invalid" ;
VAL_ 149 TCU_CrankingAuthorizationEnable 2 "Invalid" 1 "Starter enabled" 0 "Starter not enabled" ;
VAL_ 149 TCU_Clutch_Status 7 "Reserve" 6 "Reserve" 5 "Reserve" 4 "Reserve" 3 "Clutch Prepared" 2 "Clutch Closed" 1 "Clutch Closing" 0 "Clutch open" ;
VAL_ 149 TCU_GearEngagementAvailable 1 "Available" 0 "Unavailable" ;
VAL_ 149 TCU_ClutchAvailableMaximumTorque 4095 "Invalid" ;
VAL_ 149 TCU_ClutchAvailableMinimumTorque 4095 "Invalid" ;
VAL_ 149 TCU_ClutchCapacityAct 4095 "Invalid" ;
VAL_ 151 TCU_MaxFrtMotPwr_Req 8191 "Invalid" ;
VAL_ 151 TCU_Fault_Reaction_Req 15 "Fault_Reaction_Req15 离合器黏连/压力卡滞故障:发动机断油,不能跑倒挡且限制功率且限速40km/h发动机停机且离合器脱开；" 14 "Fault_Reaction_Req14 离合器黏连/压力卡滞故障:发动机断油,不能跑倒挡且限制功率且限速40km/h发动机停机；" 13 "Fault_Reaction_Req13 离合器黏连/压力卡滞故障:发动机断油,不能跑倒挡且离合器脱开且限速40km/h发动机停机；" 12 "Fault_Reaction_Req12 离合器黏连/压力卡滞故障:发动机断油,不能跑倒挡且限速40km/h发动机停机；" 11 "Fault_Reaction_Req11 离合器黏连/压力卡滞故障:发动机断油,不能跑倒挡且限制功率且离合器保持分离；" 10 "Fault_Reaction_Req10 离合器黏连/压力卡滞故障:发动机断油,不能跑倒挡且限制功率；" 9 "Fault_Reaction_Req9 离合器黏连/压力卡滞故障:发动机断油,不能跑倒挡且离合器保持分离；" 8 "Fault_Reaction_Req8 离合器黏连/压力卡滞故障:发动机断油,不能跑倒挡；" 7 "Fault_Reaction_Req7 限速40km/h，发动机断油停机且限制功率且离合器保持分开；" 6 "Fault_Reaction_Req6 限速40km/h，发动机断油停机且限制功率；" 5 "Fault_Reaction_Req5 限速40km/h，发动机断油停机且离合器保持分离；" 4 "Fault_Reaction_Req4 限速40km/h，发动机断油停机；" 3 "Fault_Reaction_Req3 离合器保持分离且限制功率；" 2 "Fault_Reaction_Req2 限制功率；" 1 "Fault_Reaction_Req1 离合器保持分离；" 0 "No Fault" ;
VAL_ 151 TCU_MaxGCUPwr_Req 4095 "Invalid" ;
VAL_ 817 TCU_OBD_Lamp_Req 3 "INVALID" 2 "RESERVED" 1 "ON" 0 "OFF" ;
VAL_ 817 TCU_FaultLamp_Req 3 "Reserve" 2 "Red-LED request" 1 "Yellow-LED request" 0 "No Request" ;
VAL_ 817 TCU_TransmissionFluidTemp 255 "Invalid" ;
VAL_ 131 EMS_EngSpdValid 1 "Valid" 0 "Invalid" ;
VAL_ 131 EMS_StartAllowed 1 "允许起动" 0 "禁止起动" ;
VAL_ 131 EMS_StopAllowed 0 "禁止停机" 1 "允许停机；" ;
VAL_ 131 EMS_engStartfailure 1 "failure" 0 "Init" ;
VAL_ 131 EMS_EngRunningStatusValid 1 "Valid" 0 "Invalid" ;
VAL_ 131 EMS_EngRunningStatus 7 "None" 6 "AUTOSTOPPING" 5 "FINISH" 4 "STOPPING" 3 "RUNNING" 2 "CRANKING" 1 "READY" 0 "STANDBY" ;
VAL_ 131 EMS_calculatedLoadValue 255 "Invalid" ;
VAL_ 131 EMS_calculatedLoadValueValid 1 "VALID" 0 "INVALID" ;
VAL_ 133 EMS_MinTorque_Workpoint_Req 4095 "Invalid" ;
VAL_ 133 EMS_MaxTorque_Workpoint_Req 4095 "Invalid" ;
VAL_ 134 EMS_FrictionTorque 4095 "Invalid" ;
VAL_ 134 EMS_FuelcutAllowed 1 "允许断油" 0 "不允许断油" ;
VAL_ 134 EMS_EngineFuelCutOff 1 "有效" 0 "无效" ;
VAL_ 134 EMS_engIdleCtrlState 1 "TRUE" 0 "FALSE" ;
VAL_ 134 EMS_EngineOverSpeed 1 "OverSpd" 0 "No OverSpd" ;
VAL_ 134 EMS_Workpoint_Req 7 "Reserve" 6 "GPF再生:（EMS自身有转速和扭矩请求，将请求的工况点目标转速和扭矩的范围发给VCU）" 5 "催化剂诊断请求（EMS有自怠速需求，工况点请求将EMS_MaxSpeed_Workpoint_Req，EMS_MinSpeed_Workpoint_Req发成相同值，EMS_MaxTorque_Workpoint_Req发最大，EMS_MinTorque_Workpoint_Req发最小值）" 4 "摩擦扭矩自学习请求（EMS有自怠速需求，工况点请求将EMS_MaxSpeed_Workpoint_Req，EMS_MinSpeed_Workpoint_Req发成相同值，EMS_MaxTorque_Workpoint_Req发最大，EMS_MinTorque_Workpoint_Req发最小值）" 3 "催化剂起燃请求（EMS自身有转速和扭矩请求，将请求的工况点目标转速和扭矩的范围发给VCU）" 2 "PCV诊断需求（EMS有自怠速需求，工况点请求将EMS_MaxSpeed_Workpoint_Req，EMS_MinSpeed_Workpoint_Req发成相同值，EMS_MaxTorque_Workpoint_Req发最大，EMS_MinTorque_Workpoint_Req发最小值）" 1 "后氧诊断需求（EMS有断油需求，工况点请求同No Request，进入断油工况后，当转速降低到怠速转速附近时，EMS需要及时退出断油请求，防止发动机熄火）" 0 "No Request（EMS_MaxSpeed_Workpoint_Req、EMS_MaxTorque_Workpoint_Req发最大值，EMS_MinSpeed_Workpoint_Req、EMS_MinTorque_Workpoint_Req发最小值；）" ;
VAL_ 134 EMS_EngFlywh 8191 "Invalid" ;
VAL_ 773 EMS_DrivingCycle 1 "激活" 0 "没有激活" ;
VAL_ 773 EMS_altitudeFactor 255 "Invalid" ;
VAL_ 773 EMS_ToltalFaultNum 255 "Invalid" ;
VAL_ 773 EMS_FuelCharingSts 3 "ERROR" 2 "None" 1 "ALLOW_INC" 0 "NOT_ALLOW_INC" ;
VAL_ 773 EMS_relifValveOpenState 3 "None" 2 "ERROR" 1 "OPEN" 0 "CLOSED" ;
VAL_ 773 EMS_WarmvalveReq 3 "reserved" 2 "Fault" 1 "open" 0 "CLOSE" ;
VAL_ 422 EMS_FanRequest 127 "Invalid" ;
VAL_ 422 EMS_MainCoolPumpReqDC 127 "Invalid" ;
VAL_ 422 EMS_ElecThermostatHeatReqDC 127 "Invalid" ;
VAL_ 422 EMS_afterRunState 3 "INVALID" 2 "RESERVED" 1 "YES" 0 "NO" ;
VAL_ 422 EMS_intakeManifoldValid 1 "VALID" 0 "INVALID" ;
VAL_ 422 EMS_engStartRq 3 "INVALID" 2 "RESERVED" 1 "START_REQUEST" 0 "NO_START_REQUEST" ;
VAL_ 775 EMS_FuelResistanceValue 1023 "Invalid" ;
VAL_ 775 EMS_OBD_Lamp_Req 3 "INVALID" 2 "Blink" 1 "ON" 0 "OFF" ;
VAL_ 775 EMS_fuelConsump100ms 4095 "Invalid" ;
VAL_ 775 EMS_engintakeAirTemp 255 "Invalid" ;
VAL_ 775 EMS_engStopTime 65535 "Invalid" ;
VAL_ 819 EMS_catalystWarmupsta 1 "TRUE" 0 "FALSE" ;
VAL_ 819 EMS_engCoolantTempValid 1 "VALID" 0 "INVALID" ;
VAL_ 819 EMS_engCoolantTemp 511 "Invalid" ;
VAL_ 819 EMS_engStartCoolantTemp 511 "Invalid" ;
VAL_ 819 EMS_SystemErrorLevel 7 "Reserve" 6 "Reserve" 5 "Shut Down Engine" 4 "Limp Home Without Torque Response" 3 "Error With Limited Performance" 2 "Error But Affect Engine Start" 1 "Slight Error" 0 "Normal without error" ;
VAL_ 1132 EMS_PressureRelief_Textinfo 3 "Reserved" 2 "Failure_SensorError" 1 "Failure_Overtime" 0 "Normal" ;
VAL_ 1132 EMS_tankState 1 "HIGH_PRESSURE" 0 "LOW_PRESSURE" ;
VAL_ 1132 EMS_EngGPFStatus 3 "保留" 2 "保留" 1 "GPF报警激活" 0 "GPF报警未激活" ;
VAL_ 1132 EMS_OilPressureAlarmLamp 1 "点亮" 0 "熄灭" ;
VAL_ 1132 EMS_GPFSootLoad 127 "Invalid" ;
VAL_ 821 GCU_GeneratorSt 7 "无效" 6 "异常" 5 "预留" 4 "预留" 3 "关闭" 2 "发电" 1 "耗电" 0 "准备状态" ;
VAL_ 821 GCU_Fault_PowerDerating 1 "Fault_Derating" 0 "Normal" ;
VAL_ 821 GCU_Fault_ShutOff_HV_Req 1 "Shutoff_Req" 0 "Nromal" ;
VAL_ 167 GCU_GeneratorSpd 524287 "Invalid" ;
VAL_ 167 GCU_GeneratorSpdValid 1 "Valid" 0 "Invalid" ;
VAL_ 167 GCU_State 6 "discharge" 5 "fault" 4 "speedctrl" 3 "torquectrl" 2 "standby" 1 "initial" 0 "reserved" ;
VAL_ 823 GCU_HV_Voltg_Free 3 "Fault(f.e. Fault of sensor)" 2 "HV-System is not voltage free(U≥20V)" 1 "HV-system is voltage free(U＜20V)" 0 "init" ;
VAL_ 864 GCU_ControllerTemp 255 "Invalid" ;
VAL_ 864 GCU_MotorTemp 255 "Invalid" ;
VAL_ 864 GCU_GeneratorFaultLamp 3 "Reserve" 2 "Red Req" 1 "Yellow Req" 0 "No Req" ;
VAL_ 864 GCU_OBD_Lamp_Req 3 "INVALID" 2 "RESERVED" 1 "ON" 0 "OFF" ;
VAL_ 864 GCU_ActiveDischargeState 3 "Discharge Failed" 2 "Discharge Succeed" 1 "Discharging" 0 "Idle" ;
VAL_ 1278 tbox_vehicleMode 15 "Invalid" 14 "Reserved" 13 "Reserved" 12 "Reserved" 11 "Reserved" 10 "Reserved" 9 "Reserved" 8 "Reserved" 7 "Reserved" 6 "Reserved" 5 "OTA mode" 4 "Collision mode (Reserved)" 3 "Transportation mode (Reserved)" 2 "Factory mode" 1 "Normal mode" 0 "Initial value" ;
VAL_ 1278 TBOX_OTAEnergyCtl 15 "Reserved" 14 "Reserved" 13 "Reserved" 12 "Reserved" 11 "Reserved" 10 "Reserved" 9 "Reserved" 8 "Reserved" 7 "Reserved" 6 "Reserved" 5 "Reserved" 4 "Reserved" 3 "Reserved" 2 "Power down request" 1 "Power on request" 0 "Inactive" ;
VAL_ 82 Tbox_engOffTimeValid 1 "VALID" 0 "INVALID" ;
VAL_ 476 ivi_centralLockCtrl 3 "INVALID" 2 "LOCK" 1 "UNLOCK" 0 "NO_COMMAND" ;
VAL_ 476 ivi_fuelPortCapOpenCtrl 3 "INVALID" 2 "RESERVED_FUELPORT" 1 "OPEN_FUELPORT" 0 "NO_COMMAND_FUELPORT" ;
VAL_ 476 ivi_chrgPortCapOpenCtrl 3 "INVALID" 2 "RESERVED" 1 "OPEN" 0 "NO_COMMAND" ;
VAL_ 476 ivi_antiTheftAlarmFormSet 3 "No Request" 2 "Reserved" 1 "Vision+Voice" 0 "Only Vision" ;
VAL_ 476 ivi_approachingUnlockCtrl 3 "INVALID" 2 "INACTIVE" 1 "ACTIVE" 0 "NO_COMMAND" ;
VAL_ 476 ivi_awayLockCtrl 3 "INVALID" 2 "INACTIVE" 1 "ACTIVE" 0 "NO_COMMAND" ;
VAL_ 476 ivi_parkAutoCloseDRLCtrl 3 "INVALID" 2 "Disable" 1 "Enable" 0 "No Request" ;
VAL_ 476 ivi_welcomeSetEnable 3 "INVALID" 2 "Enable" 1 "Disable" 0 "NO  Request" ;
VAL_ 476 ivi_welcomeOnOffSet 15 "Reserved" 14 "Reserved" 13 "Reserved" 12 "Reserved" 11 "Mode10" 10 "Mode9" 9 "Mode8" 8 "Mode7" 7 "Mode6" 6 "Mode5" 5 "Mode4" 4 "Mode3" 3 "Mode2" 2 "Mode1" 1 "OFF" 0 "Default" ;
VAL_ 476 ivi_followMeHomeSet 7 "INVALID" 4 "60S" 3 "30S" 2 "15S" 1 "OFF" 0 "NO_COMMAND" ;
VAL_ 476 ivi_WiperMaintenanceCtrl 2 "ON" 1 "OFF" 0 "No request" ;
VAL_ 476 ivi_lockAutoCloseWinCtrl 3 "INVALID" 2 "INACTIVE" 1 "ACTIVE" 0 "NO_COMMAND" ;
VAL_ 476 IVI_Backlightadjust 15 "Invalid" 14 "Reserved" 13 "Reserved" 12 "Reserved" 11 "Reserved" 10 "Level 10" 9 "Level 9" 8 "Level 8" 7 "Level 7" 6 "Level 6" 5 "Level 5" 4 "Level 4" 3 "Level 3" 2 "Level 2" 1 "Level 1" 0 "No Action" ;
VAL_ 476 ivi_VehiclePowerOFF 1 "Request" 0 "NO Request" ;
VAL_ 476 ivi_sunroofGlassCmd 7 "STOP_SUNSHADE" 6 "CLOSE_SUNSHAGE" 5 "OPEN_SUNSHADE" 4 "TILTUP_GLASS" 3 "STOP_GLASS" 2 "CLOSE_GLASS" 1 "OPEN_GLASS" 0 "NO_CMD" ;
VAL_ 476 ivi_sunroofRollshadeCtrlSelect 2 "Rollshade" 1 "Sunroof" 0 "NO Request" ;
VAL_ 476 ivi_tailgateCtrl 3 "STOP" 2 "OPEN" 1 "CLOSE" 0 "NO_COMMAND" ;
VAL_ 476 IVI_FLReadLightReq 2 "ON" 1 "OFF" 0 "No request" ;
VAL_ 476 IVI_FRReadLightReq 2 "ON" 1 "OFF" 0 "No request" ;
VAL_ 476 IVI_RLReadLightReq 2 "ON" 1 "OFF" 0 "No request" ;
VAL_ 476 IVI_RReadLightReq 2 "ON" 1 "OFF" 0 "No request" ;
VAL_ 476 IVI_ITLToplampReq 2 "ON" 1 "OFF" 0 "No request" ;
VAL_ 476 ivi_languageSet 3 "NO_COMMAND" 2 "RESERVED" 1 "ENGLISH" 0 "SIMPLIFIED_CHINESE" ;
VAL_ 476 ivi_unitSet 3 "INVALID" 2 "NO  Request" 1 "MILE" 0 "KM" ;
VAL_ 476 ivi_OutsideLockAlarmFormSet 3 "No Request" 2 "Reserved" 1 "Only Vision" 0 "Vision+Voice" ;
VAL_ 1022 ivi_timeValid 1 "VALID" 0 "INVALID" ;
VAL_ 1022 ivi_altitude 127 "Invalid" ;
VAL_ 1022 IVI_EetSceneModeSts 15 "Reserved" 14 "Reserved" 13 "Reserved" 12 "Reserved" 11 "CampMode" 10 "MovieMode" 9 "NotPowerOffMode" 8 "WaitingMode" 7 "SelfCarWashMode" 6 "ReceptionMode" 5 "VitalityMode" 4 "RearRightNapMode" 3 "RearLeftNapMode" 2 "RearLeftRighNapMode" 1 "FrontNapMode" 0 "init" ;
VAL_ 987 bcm_fuelCapSts 3 "None" 2 "TAPERROR" 1 "OPEN" 0 "CLOSED" ;
VAL_ 987 BCM_refuelReq 1 "Request" 0 "No request" ;
VAL_ 987 bcm_hoodSts 1 "Opened" 0 "Closed" ;
VAL_ 987 rls_lightSWReason 7 "Reserved" 6 "Reserved" 5 "Reserved" 4 "Darkstart" 3 "Tunnel" 2 "Dark" 1 "Others" 0 "Day" ;
VAL_ 987 ebs_U_BATT 16383 "Invalid" ;
VAL_ 987 ic_oilPercent 255 "Invalid" ;
VAL_ 987 IC_OilSensorResistance 511 "Invalid" ;
VAL_ 987 ic_oilPercentFail 3 "SHORT_POWER_OR_OPEN_CIRCURT" 2 "OUT_RANGE" 1 "SHORT_GROUND" 0 "NORMAL" ;
VAL_ 987 AC_WarmWindReq 1 "请求" 0 "无请求" ;
VAL_ 987 AC_ambientTempValid 1 "VALID" 0 "INVALID" ;
VAL_ 987 AC_Warmvalvestate 3 "reserved" 2 "Fault" 1 "open" 0 "CLOSE" ;
VAL_ 987 AC_ambientTemp 255 "Invalid" ;
VAL_ 514 ic_totalMileage 16777215 "Invalid" ;
VAL_ 514 ic_totalMileageValid 1 "VALID" 0 "INVALID" ;
VAL_ 514 LgtAValSts 3 "Initializing" 2 "Reserved" 1 "Valid" 0 "Invalid" ;
VAL_ 514 EPBS_FaultLamp 3 "RESERVED_EPB1" 2 "LAMP_FLASH" 1 "LAMP_ON" 0 "LAMP_OFF" ;
VAL_ 514 EPBS_Sts 7 "RESERVED_EPB14" 6 "UNKNOWN" 5 "COMPLETELY RELEASED" 4 "RELEASING" 3 "PARKING" 2 "RELEASED" 1 "PARKED" 0 "DEFAULT" ;
VAL_ 514 EPBS_BrakeSwInfo 3 "Switch fault" 2 "Apply request" 1 "Release request" 0 "No request" ;
VAL_ 705 bcm_pepsPowerMode 7 "INVALID_POWERMODE" 6 "RESERVE_POWERMODE3" 5 "RESERVE_POWERMODE2" 4 "RESERVE_POWERMODE1" 3 "Remote ON_POWERMODE" 2 "Local ON_POWERMODE" 1 "OFF_POWERMODE" 0 "DEFAULT_POWERMODE" ;
VAL_ 705 bcm_IMMOReleaseIndication 1 "INDICATION" 0 "NO_INDICATION" ;
VAL_ 705 bcm_pepsKeyNotInCarInd 1 "WARNING" 0 "NO_WARNING" ;
VAL_ 705 bcm_keyValid 2 "INVALID" 1 "YES" 0 "NO" ;
VAL_ 705 bcm_pepsKeySerchFailInd 1 "WARNING" 0 "NO_WARNING" ;
VAL_ 705 bcm_pepsKeyCloserInd 1 "WARNING" 0 "NO_WARNING" ;
VAL_ 705 bcm_pepsFobLowBatWarning 1 "WARNING" 0 "NO_WARNING" ;
VAL_ 705 bcm_pepsPowerRelayErrWarning 1 "WARNING" 0 "NO_WARNING" ;
VAL_ 705 bcm_IndicationPressBrake 1 "Warning" 0 "No warning" ;
VAL_ 705 bcm_LowFrequencyAntennaFault 1 "Fault" 0 "Normal" ;
VAL_ 705 BCM_RainWinowCloseWarning 1 "Warning" 0 "No warning" ;
VAL_ 705 BCM_KL15RelayReq 1 "request" 0 "no request" ;
VAL_ 705 bcm_remoteMode 3 "Reserved" 2 "REMOTE" 1 "NORMAL" 0 "INVALID" ;
VAL_ 705 bcm_ble_response 3 "Reserved" 2 "Anti theft authentication success(防盗认证成功)" 1 "Anti theft authentication failed(防盗认证失败)" 0 "default" ;
VAL_ 705 BCM_RKEWindowCmd 3 "Windows stop(停止遥控升降窗动作)" 2 "Window Down" 1 "Window Up" 0 "Default" ;
VAL_ 705 bcm_srSsAndWindowsEnable 1 "SUNroof and Window Enable" 0 "SUNroof and Window Disable" ;
VAL_ 705 bcm_rke_fuelPortCapOpenCtrl 3 "INVALID" 2 "RESERVED" 1 "OPEN_FUELPORT" 0 "NO_COMMAND_FUELPORT" ;
VAL_ 705 bcm_pepsKeyInCarInd 1 "WARNING" 0 "NO_WARNING" ;
VAL_ 705 bcm_tbox_response 3 "Reserved" 2 "Anti theft authentication success(防盗认证成功)" 1 "Anti theft authentication failed(防盗认证失败)" 0 "default" ;
VAL_ 705 bcm_approachingUnlockFedb 3 "INVALID" 2 "INACTIVE" 1 "ACTIVE" 0 "Default" ;
VAL_ 705 BCM_sunroofGlassCmd 7 "StopShade" 6 "CloseShade" 5 "OpenShade" 4 "TiltUpGlass" 3 "StopGlass" 2 "CloseGlass" 1 "OpenGlass" 0 "NoCmd" ;
VAL_ 705 bcm_followMeHomeFedb 7 "INVALID" 4 "60S" 3 "30S" 2 "15S" 1 "OFF" 0 "RESERVED" ;
VAL_ 705 bcm_awayLockFeedback 3 "INVALID" 2 "INACTIVE" 1 "ACTIVE" 0 "RESERVED" ;
VAL_ 705 bcm_PepsKeyIncarIndi 3 "not searched" 2 "Key not in car" 1 "Key in car" 0 "default" ;
VAL_ 705 bcm_GearPUnlockFeedback 3 "INVALID" 2 "INACTIVE" 1 "ACTIVE" 0 "RESERVED" ;
VAL_ 800 swm_highbeam 1 "ON" 0 "OFF" ;
VAL_ 800 swm_overtakingLight 1 "ON" 0 "OFF" ;
VAL_ 800 swm_turnSW 3 "Reserve" 2 "Turn Right" 1 "Turn Left" 0 "OFF" ;
VAL_ 800 swm_changeLaneSW 3 "Reserve" 2 "Change lane to Right" 1 "Change lane to left" 0 "OFF" ;
VAL_ 800 swm_frontWashing 1 "ON" 0 "OFF" ;
VAL_ 800 SWM_FrontWiperSwitch 7 "Invalid" 6 "Reserved" 5 "Reserved" 4 "High speed" 3 "Low speed" 2 "Auto" 1 "MIST" 0 "OFF" ;
VAL_ 800 SWM_RearWiper 2 "Uniform velocity" 1 "Intermittent" 0 "OFF" ;
VAL_ 800 SWM_RearWashing 1 "ON" 0 "OFF" ;
VAL_ 800 SWM_Sensitivity 7 "Invalid" 6 "Reserved" 5 "Reserved" 4 "Reserved" 3 "Sensitivity High" 2 "Sensitivity Middle" 1 "Sensitivity Normal" 0 "Sensitivity Low" ;
VAL_ 322 IPB_wheelSpeedFL 8191 "Invalid" ;
VAL_ 322 IPB_wheelSpeedFLValid 1 "VALID" 0 "INVALID" ;
VAL_ 322 IPB_wheelSpeedFR 8191 "Invalid" ;
VAL_ 322 IPB_wheelSpeedFRValid 1 "VALID" 0 "INVALID" ;
VAL_ 290 IPB_wheelSpeedRL 8191 "Invalid" ;
VAL_ 290 IPB_wheelSpeedRLValid 1 "VALID" 0 "INVALID" ;
VAL_ 290 IPB_wheelSpeedRR 8191 "Invalid" ;
VAL_ 290 IPB_wheelSpeedRRValid 1 "VALID" 0 "INVALID" ;
VAL_ 160 IPB_vehicleSpeed 8191 "Invalid" ;
VAL_ 160 IPB_vehicleSpeedValid 1 "VALID" 0 "INVALID" ;
VAL_ 160 IPB_absFault 1 "FAULT" 0 "NORMAL" ;
VAL_ 160 IPB_absActive 1 "ACTIVE" 0 "INACTIVE" ;
VAL_ 160 IPB_vdcActive 1 "ACTIVE" 0 "INACTIVE" ;
VAL_ 160 IPB_tcsActive 1 "ACTIVE" 0 "INACTIVE" ;
VAL_ 160 IPB_avhModeWSts 3 "SecondFootMode and Active" 2 "AutoHoldMode and Active" 1 "SecondFootMode and STANDBY" 0 "AutoHoldMode and STANDBY" ;
VAL_ 160 IPB_avhAvailable 1 "AVAILABLE" 0 "NOT_AVAILABLE" ;
VAL_ 160 IPB_cdpActive 1 "ACTIVE" 0 "INACTIVE" ;
VAL_ 160 IPB_cdpAvailable 1 "AVAILABLE" 0 "NOT_AVAILABLE" ;
VAL_ 160 IPB_hdcAvailable 1 "AVAILABLE" 0 "NOT_AVAILABLE" ;
VAL_ 160 IPB_epbRequest 2 "RELEASE" 1 "APPLY" 0 "NO_COMMAND" ;
VAL_ 160 IPB_vehicleStandstill 2 "RESERVED" 1 "STANDSTILL" 0 "NOT_STANDSTILL" ;
VAL_ 160 IPB_vehicleStandstillValid 1 "VALID" 0 "INVALID" ;
VAL_ 160 IPB_ModeSts 1 "SPORT" 0 "COMFORT" ;
VAL_ 160 IPB_brakelightRequest 1 "ILLUMINATE" 0 "NOT_ILLUMINATE" ;
VAL_ 160 IPB_hdcSts 3 "Reserved" 2 "On active braking" 1 "On not active braking" 0 "OFF" ;
VAL_ 160 IPB_hhcActive 1 "ACTIVE" 0 "INACTIVE" ;
VAL_ 160 IPB_hhcAvailable 1 "AVAILABLE" 0 "NOT_AVAILABLE" ;
VAL_ 160 IPB_ebdFault 1 "FAULT" 0 "NOMAL" ;
VAL_ 160 IPB_ebd_active 1 "Active" 0 "Not active" ;
VAL_ 160 IPB_ESCoffSts 1 "ON" 0 "OFF" ;
VAL_ 160 IPB_escFault 1 "FAULT" 0 "NOMAL" ;
VAL_ 160 IPB_haz_active 1 "ACTIVE" 0 "INACTIVE" ;
VAL_ 160 IPB_hazErrorSt 1 "Error" 0 "No error" ;
VAL_ 160 IPB_hba_active 1 "Active" 0 "Not active" ;
VAL_ 160 IPB_dtcActive 1 "ACTIVE" 0 "INACTIVE" ;
VAL_ 160 IPB_esclampdisplay 2 "ESP lamp FLASH" 1 "ESP lamp OFF" 0 "ESP lamp ON" ;
VAL_ 160 IPB_BDWActive 1 "ACTIVE" 0 "INACTIVE" ;
VAL_ 160 IPB_HRBActive 1 "ACTIVE" 0 "INACTIVE" ;
VAL_ 179 acu_crashOutputStsValid 3 "reserved" 2 "reserved" 1 "VALID" 0 "INVALID" ;
VAL_ 179 acu_crashOutputSts 255 "Reserved" 254 "Reserved" 253 "Reserved" 252 "Reserved" 251 "Reserved" 250 "Reserved" 249 "Reserved" 248 "Reserved" 247 "Reserved" 246 "Reserved" 245 "Reserved" 244 "Reserved" 243 "Reserved" 242 "Reserved" 241 "Reserved" 240 "Reserved" 239 "Reserved" 238 "Reserved" 237 "Reserved" 236 "Reserved" 235 "Reserved" 234 "Reserved" 233 "Reserved" 232 "Reserved" 231 "Reserved" 230 "Reserved" 229 "Reserved" 228 "Reserved" 227 "Reserved" 226 "Reserved" 225 "Reserved" 224 "Reserved" 223 "Reserved" 222 "Reserved" 221 "Reserved" 220 "Reserved" 219 "Reserved" 218 "Reserved" 217 "Reserved" 216 "Reserved" 215 "Reserved" 214 "Reserved" 213 "Reserved" 212 "Reserved" 211 "Reserved" 210 "Reserved" 209 "Reserved" 208 "Reserved" 207 "Reserved" 206 "Reserved" 205 "Reserved" 204 "Reserved" 203 "Reserved" 202 "Reserved" 201 "Reserved" 200 "Reserved" 199 "Reserved" 198 "Reserved" 197 "Reserved" 196 "Reserved" 195 "Reserved" 194 "Reserved" 193 "Reserved" 192 "Reserved" 191 "Reserved" 190 "Reserved" 189 "Reserved" 188 "Reserved" 187 "Reserved" 186 "Reserved" 185 "Reserved" 184 "Reserved" 183 "Reserved" 182 "Reserved" 181 "Reserved" 180 "Reserved" 179 "Reserved" 178 "Reserved" 177 "Reserved" 176 "Reserved" 175 "Reserved" 174 "Reserved" 173 "Reserved" 172 "Reserved" 171 "Reserved" 170 "Reserved" 169 "Reserved" 168 "Reserved" 167 "Reserved" 166 "Reserved" 165 "Reserved" 164 "Reserved" 163 "Reserved" 162 "Reserved" 161 "Reserved" 160 "Reserved" 159 "Reserved" 158 "Reserved" 157 "Reserved" 156 "Reserved" 155 "Reserved" 154 "Reserved" 153 "Reserved" 152 "Reserved" 151 "Reserved" 150 "Reserved" 149 "Reserved" 148 "Reserved" 147 "Reserved" 146 "Reserved" 145 "Reserved" 144 "Reserved" 143 "Reserved" 142 "Reserved" 141 "Reserved" 140 "Reserved" 139 "Reserved" 138 "Reserved" 137 "Reserved" 136 "Reserved" 135 "Reserved" 134 "Reserved" 133 "Reserved" 132 "Reserved" 131 "Reserved" 130 "Reserved" 129 "Reserved" 128 "Reserved" 127 "Reserved" 126 "Reserved" 125 "Reserved" 124 "Reserved" 123 "Reserved" 122 "Reserved" 121 "Reserved" 120 "Reserved" 119 "Reserved" 118 "Reserved" 117 "Reserved" 116 "Reserved" 115 "Reserved" 114 "Reserved" 113 "Reserved" 112 "Reserved" 111 "Reserved" 110 "Reserved" 109 "Reserved" 108 "Reserved" 107 "Reserved" 106 "Reserved" 105 "Reserved" 104 "Reserved" 103 "Reserved" 102 "Reserved" 101 "Reserved" 100 "Reserved" 99 "Reserved" 98 "Reserved" 97 "Reserved" 96 "Reserved" 95 "Reserved" 94 "Reserved" 93 "Reserved" 92 "Reserved" 91 "Reserved" 90 "Reserved" 89 "Reserved" 88 "Reserved" 87 "Reserved" 86 "Reserved" 85 "Reserved" 84 "Reserved" 83 "Reserved" 82 "Reserved" 81 "Reserved" 80 "Reserved" 79 "Reserved" 78 "Reserved" 77 "Reserved" 76 "Reserved" 75 "Reserved" 74 "Reserved" 73 "Reserved" 72 "Reserved" 71 "Reserved" 70 "Reserved" 69 "Reserved" 68 "Reserved" 67 "Reserved" 66 "Reserved" 65 "Reserved" 64 "Reserved" 63 "Reserved" 62 "Reserved" 61 "Reserved" 60 "Reserved" 59 "Reserved" 58 "Reserved" 57 "Reserved" 56 "Reserved" 55 "Reserved" 54 "Reserved" 53 "Reserved" 52 "Reserved" 51 "Reserved" 50 "Reserved" 49 "Reserved" 48 "Reserved" 47 "Reserved" 46 "Reserved" 45 "Reserved" 44 "Reserved" 43 "Reserved" 42 "Reserved" 41 "Reserved" 40 "Reserved" 39 "Reserved" 38 "Reserved" 37 "Reserved" 36 "Reserved" 35 "Reserved" 34 "Reserved" 33 "Reserved" 32 "Reserved" 31 "Reserved" 30 "Reserved" 29 "Reserved" 28 "Reserved" 27 "Reserved" 26 "Reserved" 25 "Reserved" 24 "Reserved" 23 "Reserved" 22 "Reserved" 21 "Reserved" 20 "Reserved" 19 "Reserved" 18 "Reserved" 17 "Reserved" 16 "Reserved" 15 "Rear + Side + Front + BPT" 14 "Rear + Side + Front" 13 "Rear + Side + BPT" 12 "Rear + Side" 11 "Rear + Front + BPT" 10 "Rear + Front" 9 "Rear + BPT" 8 "Rear Crash" 7 "Side + Front + BPT" 6 "Side + Front" 5 "Side + BPT" 4 "Side Crash" 3 "Front + BPT" 2 "Front Crash" 1 "BPT Crash" 0 "No Crash" ;
VAL_ 179 eps_sasSteeringAngle 65535 "Invalid" ;
VAL_ 179 eps_sasSteeringAngleValid 1 "VALID" 0 "INVALID" ;
VAL_ 1620 PDCM_SPT2_RMR 1 "Repeat Message State requested" 0 "Repeat Message State not requested" ;
VAL_ 1620 PDCM_SPT2_AWB 1 "Node has woken up the network (active Wakeup)" 0 "Node has not woken up the network (passive wakeup)" ;
VAL_ 1587 MCUF_RMR 1 "Repeat Message State requested" 0 "Repeat Message State not requested" ;
VAL_ 1587 MCUF_AWB 1 "Node has woken up the network (active Wakeup)" 0 "Node has not woken up the network (passive wakeup)" ;
VAL_ 1586 MCUR_RMR 1 "Repeat Message State requested" 0 "Repeat Message State not requested" ;
VAL_ 1586 MCUR_AWB 1 "Node has woken up the network (active Wakeup)" 0 "Node has not woken up the network (passive wakeup)" ;
VAL_ 1561 SWM_RMR 1 "Repeat Message State requested" 0 "Repeat Message State not requested" ;
VAL_ 1561 SWM_AWB 1 "Node has woken up the network (active Wakeup)" 0 "Node has not woken up the network (passive wakeup)" ;
VAL_ 1596 GCU_RMR 1 "Repeat Message State requested" 0 "Repeat Message State not requested" ;
VAL_ 1596 GCU_AWB 1 "Node has woken up the network (active Wakeup)" 0 "Node has not woken up the network (passive wakeup)" ;
